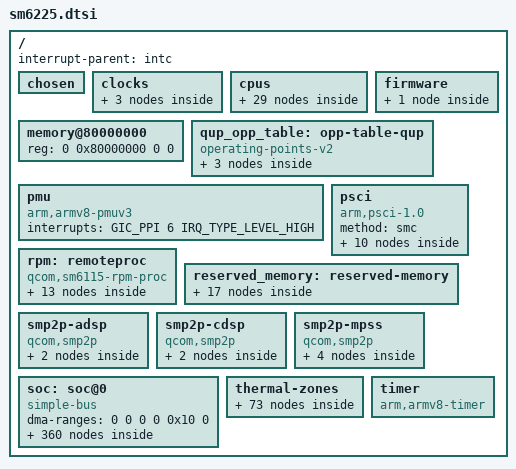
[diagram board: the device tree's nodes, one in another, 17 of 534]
// SPDX-License-Identifier: (GPL-2.0+ OR BSD-3-Clause)
/*
 * SoC device tree for SM6225
 * Copyright (c) 2025, Ivaylo Ivanov <ivo.ivanov.ivanov1@gmail.com>
 */

#include <dt-bindings/clock/qcom,gcc-sm6225.h>
#include <dt-bindings/clock/qcom,dispcc-sm6225.h>
#include <dt-bindings/clock/qcom,sm6225-gpucc.h>
#include <dt-bindings/clock/qcom,rpmcc.h>
#include <dt-bindings/dma/qcom-gpi.h>
#include <dt-bindings/firmware/qcom,scm.h>
#include <dt-bindings/gpio/gpio.h>
#include <dt-bindings/interconnect/qcom,rpm-icc.h>
#include <dt-bindings/interconnect/qcom,sm6115.h>
#include <dt-bindings/interrupt-controller/arm-gic.h>
#include <dt-bindings/power/qcom-rpmpd.h>
#include <dt-bindings/soc/qcom,gpr.h>
#include <dt-bindings/sound/qcom,q6dsp-lpass-ports.h>
#include <dt-bindings/thermal/thermal.h>

/ {
	interrupt-parent = <&intc>;

	#address-cells = <2>;
	#size-cells = <2>;

	chosen { };

	clocks {
		xo_board: xo-board {
			compatible = "fixed-clock";
			#clock-cells = <0>;
		};

		sleep_clk: sleep-clk {
			compatible = "fixed-clock";
			#clock-cells = <0>;
		};

		usb3_phy_wrapper_gcc_usb30_pipe_clk: usb3_phy_wrapper_gcc_usb30_pipe_clk {
			compatible = "fixed-clock";
			#clock-cells = <0>;
			clock-frequency = <1000>;
			clock-output-names = "usb3_phy_wrapper_gcc_usb30_pipe_clk";
		};
	};

	cpus {
		#address-cells = <2>;
		#size-cells = <0>;

		cpu0: cpu@0 {
			device_type = "cpu";
			compatible = "qcom,kryo260";
			reg = <0x0 0x0>;
			clocks = <&cpufreq_hw 0>;
			capacity-dmips-mhz = <1024>;
			dynamic-power-coefficient = <100>;
			enable-method = "psci";
			next-level-cache = <&l2_0>;
			qcom,freq-domain = <&cpufreq_hw 0>;
			power-domains = <&cpu_pd0>;
			power-domain-names = "psci";
			l2_0: l2-cache {
				compatible = "cache";
				cache-level = <2>;
				cache-unified;
			};
		};

		cpu1: cpu@1 {
			device_type = "cpu";
			compatible = "qcom,kryo260";
			reg = <0x0 0x1>;
			clocks = <&cpufreq_hw 0>;
			capacity-dmips-mhz = <1024>;
			dynamic-power-coefficient = <100>;
			enable-method = "psci";
			next-level-cache = <&l2_0>;
			qcom,freq-domain = <&cpufreq_hw 0>;
			power-domains = <&cpu_pd1>;
			power-domain-names = "psci";
		};

		cpu2: cpu@2 {
			device_type = "cpu";
			compatible = "qcom,kryo260";
			reg = <0x0 0x2>;
			clocks = <&cpufreq_hw 0>;
			capacity-dmips-mhz = <1024>;
			dynamic-power-coefficient = <100>;
			enable-method = "psci";
			next-level-cache = <&l2_0>;
			qcom,freq-domain = <&cpufreq_hw 0>;
			power-domains = <&cpu_pd2>;
			power-domain-names = "psci";
		};

		cpu3: cpu@3 {
			device_type = "cpu";
			compatible = "qcom,kryo260";
			reg = <0x0 0x3>;
			clocks = <&cpufreq_hw 0>;
			capacity-dmips-mhz = <1024>;
			dynamic-power-coefficient = <100>;
			enable-method = "psci";
			next-level-cache = <&l2_0>;
			qcom,freq-domain = <&cpufreq_hw 0>;
			power-domains = <&cpu_pd3>;
			power-domain-names = "psci";
		};

		cpu4: cpu@100 {
			device_type = "cpu";
			compatible = "qcom,kryo260";
			reg = <0x0 0x100>;
			clocks = <&cpufreq_hw 1>;
			enable-method = "psci";
			capacity-dmips-mhz = <1638>;
			dynamic-power-coefficient = <282>;
			next-level-cache = <&l2_1>;
			qcom,freq-domain = <&cpufreq_hw 1>;
			power-domains = <&cpu_pd4>;
			power-domain-names = "psci";
			l2_1: l2-cache {
				compatible = "cache";
				cache-level = <2>;
				cache-unified;
			};
		};

		cpu5: cpu@101 {
			device_type = "cpu";
			compatible = "qcom,kryo260";
			reg = <0x0 0x101>;
			clocks = <&cpufreq_hw 1>;
			capacity-dmips-mhz = <1638>;
			dynamic-power-coefficient = <282>;
			enable-method = "psci";
			next-level-cache = <&l2_1>;
			qcom,freq-domain = <&cpufreq_hw 1>;
			power-domains = <&cpu_pd5>;
			power-domain-names = "psci";
		};

		cpu6: cpu@102 {
			device_type = "cpu";
			compatible = "qcom,kryo260";
			reg = <0x0 0x102>;
			clocks = <&cpufreq_hw 1>;
			capacity-dmips-mhz = <1638>;
			dynamic-power-coefficient = <282>;
			enable-method = "psci";
			next-level-cache = <&l2_1>;
			qcom,freq-domain = <&cpufreq_hw 1>;
			power-domains = <&cpu_pd6>;
			power-domain-names = "psci";
		};

		cpu7: cpu@103 {
			device_type = "cpu";
			compatible = "qcom,kryo260";
			reg = <0x0 0x103>;
			clocks = <&cpufreq_hw 1>;
			capacity-dmips-mhz = <1638>;
			dynamic-power-coefficient = <282>;
			enable-method = "psci";
			next-level-cache = <&l2_1>;
			qcom,freq-domain = <&cpufreq_hw 1>;
			power-domains = <&cpu_pd7>;
			power-domain-names = "psci";
		};

		cpu-map {
			cluster0 {
				core0 {
					cpu = <&cpu0>;
				};

				core1 {
					cpu = <&cpu1>;
				};

				core2 {
					cpu = <&cpu2>;
				};

				core3 {
					cpu = <&cpu3>;
				};
			};

			cluster1 {
				core0 {
					cpu = <&cpu4>;
				};

				core1 {
					cpu = <&cpu5>;
				};

				core2 {
					cpu = <&cpu6>;
				};

				core3 {
					cpu = <&cpu7>;
				};
			};
		};

		idle-states {
			entry-method = "psci";

			little_cpu_sleep_0: cpu-sleep-0-0 {
				compatible = "arm,idle-state";
				idle-state-name = "silver-rail-power-collapse";
				arm,psci-suspend-param = <0x40000003>;
				entry-latency-us = <290>;
				exit-latency-us = <376>;
				min-residency-us = <1182>;
				local-timer-stop;
			};

			big_cpu_sleep_0: cpu-sleep-1-0 {
				compatible = "arm,idle-state";
				idle-state-name = "gold-rail-power-collapse";
				arm,psci-suspend-param = <0x40000003>;
				entry-latency-us = <297>;
				exit-latency-us = <324>;
				min-residency-us = <1110>;
				local-timer-stop;
			};
		};

		domain-idle-states {
			cluster_0_sleep_0: cluster-sleep-0-0 {
				/* GDHS */
				compatible = "domain-idle-state";
				arm,psci-suspend-param = <0x40000022>;
				entry-latency-us = <360>;
				exit-latency-us = <421>;
				min-residency-us = <782>;
			};

			cluster_0_sleep_1: cluster-sleep-0-1 {
				/* Power Collapse */
				compatible = "domain-idle-state";
				arm,psci-suspend-param = <0x41000044>;
				entry-latency-us = <800>;
				exit-latency-us = <2118>;
				min-residency-us = <7376>;
			};

			cluster_1_sleep_0: cluster-sleep-1-0 {
				/* GDHS */
				compatible = "domain-idle-state";
				arm,psci-suspend-param = <0x40000042>;
				entry-latency-us = <314>;
				exit-latency-us = <345>;
				min-residency-us = <660>;
			};

			cluster_1_sleep_1: cluster-sleep-1-1 {
				/* Power Collapse */
				compatible = "domain-idle-state";
				arm,psci-suspend-param = <0x41000044>;
				entry-latency-us = <640>;
				exit-latency-us = <1654>;
				min-residency-us = <8094>;
			};
		};
	};

	firmware {
		scm: scm {
			compatible = "qcom,scm-sm6115", "qcom,scm";
			#reset-cells = <1>;
			interconnects = <&system_noc MASTER_CRYPTO_CORE0 RPM_ALWAYS_TAG
					 &bimc SLAVE_EBI_CH0 RPM_ALWAYS_TAG>;
		};
	};

	memory@80000000 {
		device_type = "memory";
		/* We expect the bootloader to fill in the size */
		reg = <0 0x80000000 0 0>;
	};

	qup_opp_table: opp-table-qup {
		compatible = "operating-points-v2";

		opp-75000000 {
			opp-hz = /bits/ 64 <75000000>;
			required-opps = <&rpmpd_opp_low_svs>;
		};

		opp-100000000 {
			opp-hz = /bits/ 64 <100000000>;
			required-opps = <&rpmpd_opp_svs>;
		};

		opp-128000000 {
			opp-hz = /bits/ 64 <128000000>;
			required-opps = <&rpmpd_opp_nom>;
		};
	};

	pmu {
		compatible = "arm,armv8-pmuv3";
		interrupts = <GIC_PPI 6 IRQ_TYPE_LEVEL_HIGH>;
	};

	psci {
		compatible = "arm,psci-1.0";
		method = "smc";

		cpu_pd0: power-domain-cpu0 {
			#power-domain-cells = <0>;
			power-domains = <&cluster_0_pd>;
			domain-idle-states = <&little_cpu_sleep_0>;
		};

		cpu_pd1: power-domain-cpu1 {
			#power-domain-cells = <0>;
			power-domains = <&cluster_0_pd>;
			domain-idle-states = <&little_cpu_sleep_0>;
		};

		cpu_pd2: power-domain-cpu2 {
			#power-domain-cells = <0>;
			power-domains = <&cluster_0_pd>;
			domain-idle-states = <&little_cpu_sleep_0>;
		};

		cpu_pd3: power-domain-cpu3 {
			#power-domain-cells = <0>;
			power-domains = <&cluster_0_pd>;
			domain-idle-states = <&little_cpu_sleep_0>;
		};

		cpu_pd4: power-domain-cpu4 {
			#power-domain-cells = <0>;
			power-domains = <&cluster_1_pd>;
			domain-idle-states = <&big_cpu_sleep_0>;
		};

		cpu_pd5: power-domain-cpu5 {
			#power-domain-cells = <0>;
			power-domains = <&cluster_1_pd>;
			domain-idle-states = <&big_cpu_sleep_0>;
		};

		cpu_pd6: power-domain-cpu6 {
			#power-domain-cells = <0>;
			power-domains = <&cluster_1_pd>;
			domain-idle-states = <&big_cpu_sleep_0>;
		};

		cpu_pd7: power-domain-cpu7 {
			#power-domain-cells = <0>;
			power-domains = <&cluster_1_pd>;
			domain-idle-states = <&big_cpu_sleep_0>;
		};

		cluster_0_pd: power-domain-cpu-cluster0 {
			#power-domain-cells = <0>;
			domain-idle-states = <&cluster_0_sleep_0>, <&cluster_0_sleep_1>;
		};

		cluster_1_pd: power-domain-cpu-cluster1 {
			#power-domain-cells = <0>;
			domain-idle-states = <&cluster_1_sleep_0>, <&cluster_1_sleep_1>;
		};
	};

	rpm: remoteproc {
		compatible = "qcom,sm6115-rpm-proc", "qcom,rpm-proc";

		glink-edge {
			compatible = "qcom,glink-rpm";

			interrupts = <GIC_SPI 194 IRQ_TYPE_EDGE_RISING>;
			qcom,rpm-msg-ram = <&rpm_msg_ram>;
			mboxes = <&apcs_glb 0>;

			rpm_requests: rpm-requests {
				compatible = "qcom,rpm-sm6115", "qcom,glink-smd-rpm";
				qcom,glink-channels = "rpm_requests";

				rpmcc: clock-controller {
					compatible = "qcom,rpmcc-sm6115", "qcom,rpmcc";
					clocks = <&xo_board>;
					clock-names = "xo";
					#clock-cells = <1>;
				};

				rpmpd: power-controller {
					compatible = "qcom,sm6115-rpmpd";
					#power-domain-cells = <1>;
					operating-points-v2 = <&rpmpd_opp_table>;

					rpmpd_opp_table: opp-table {
						compatible = "operating-points-v2";

						rpmpd_opp_min_svs: opp1 {
							opp-level = <RPM_SMD_LEVEL_MIN_SVS>;
						};

						rpmpd_opp_low_svs: opp2 {
							opp-level = <RPM_SMD_LEVEL_LOW_SVS>;
						};

						rpmpd_opp_svs: opp3 {
							opp-level = <RPM_SMD_LEVEL_SVS>;
						};

						rpmpd_opp_svs_plus: opp4 {
							opp-level = <RPM_SMD_LEVEL_SVS_PLUS>;
						};

						rpmpd_opp_nom: opp5 {
							opp-level = <RPM_SMD_LEVEL_NOM>;
						};

						rpmpd_opp_nom_plus: opp6 {
							opp-level = <RPM_SMD_LEVEL_NOM_PLUS>;
						};

						rpmpd_opp_turbo: opp7 {
							opp-level = <RPM_SMD_LEVEL_TURBO>;
						};

						rpmpd_opp_turbo_plus: opp8 {
							opp-level = <RPM_SMD_LEVEL_TURBO_NO_CPR>;
						};
					};
				};
			};
		};
	};

	reserved_memory: reserved-memory {
		#address-cells = <2>;
		#size-cells = <2>;
		ranges;

		hyp_mem: memory@45700000 {
			reg = <0x0 0x45700000 0x0 0x600000>;
			no-map;
		};

		xbl_aop_mem: memory@45e00000 {
			reg = <0x0 0x45e00000 0x0 0x140000>;
			no-map;
		};

		sec_apps_mem: memory@45fff000 {
			reg = <0x0 0x45fff000 0x0 0x1000>;
			no-map;
		};

		smem_mem: memory@46000000 {
			compatible = "qcom,smem";
			reg = <0x0 0x46000000 0x0 0x200000>;
			no-map;

			hwlocks = <&tcsr_mutex 3>;
			qcom,rpm-msg-ram = <&rpm_msg_ram>;
		};

		cdsp_sec_regions: memory@46200000 {
			reg = <0x0 0x46200000 0x0 0x1e00000>;
			no-map;
		};

		pil_modem_mem: memory@4ab00000 {
			reg = <0x0 0x4ab00000 0x0 0x6900000>;
			no-map;
		};

		pil_video_mem: memory@51400000 {
			reg = <0x0 0x51400000 0x0 0x500000>;
			no-map;
		};

		wlan_msa_mem: memory@51900000 {
			reg = <0x0 0x51900000 0x0 0x100000>;
			no-map;
		};

		pil_cdsp_mem: memory@51a00000 {
			reg = <0x0 0x51a00000 0x0 0x1e00000>;
			no-map;
		};

		pil_adsp_mem: memory@53800000 {
			reg = <0x0 0x53800000 0x0 0x2e00000>;
			no-map;
		};

		pil_ipa_fw_mem: memory@56600000 {
			reg = <0x0 0x56600000 0x0 0x10000>;
			no-map;
		};

		// pil_ipa_gsi_mem: memory@55610000 {
		// 	reg = <0x0 0x55610000 0x0 0x5000>;
		// 	no-map;
		// };

		pil_gpu_mem: memory@56615000 {
			reg = <0x0 0x56615000 0x0 0x2000>;
			no-map;
		};

		cont_splash_memory: memory@5c000000 {
			reg = <0x0 0x5c000000 0x0 0x00f00000>;
			no-map;
		};

		dfps_data_memory: memory@5cf00000 {
			reg = <0x0 0x5cf00000 0x0 0x0100000>;
			no-map;
		};

		removed_mem: memory@60000000 {
			reg = <0x0 0x60000000 0x0 0x3900000>;
			no-map;
		};

		rmtfs_mem: memory@89b01000 {
			compatible = "qcom,rmtfs-mem";
			reg = <0x0 0x89b01000 0x0 0x300000>;
			no-map;

			qcom,client-id = <1>;
			qcom,vmid = <QCOM_SCM_VMID_MSS_MSA QCOM_SCM_VMID_NAV>;
		};

		/* The ADSP audio PD's remote heap, as stock's adsp_region */
		adsp_rpc_remote_heap_mem: adsp-rpc-remote-heap {
			compatible = "shared-dma-pool";
			alloc-ranges = <0x0 0x0 0x0 0xffffffff>;
			reusable;
			alignment = <0x0 0x400000>;
			size = <0x0 0x800000>;
		};
	};

	smp2p-adsp {
		compatible = "qcom,smp2p";
		qcom,smem = <443>, <429>;

		interrupts = <GIC_SPI 279 IRQ_TYPE_EDGE_RISING>;

		mboxes = <&apcs_glb 10>;

		qcom,local-pid = <0>;
		qcom,remote-pid = <2>;

		adsp_smp2p_out: master-kernel {
			qcom,entry-name = "master-kernel";
			#qcom,smem-state-cells = <1>;
		};

		adsp_smp2p_in: slave-kernel {
			qcom,entry-name = "slave-kernel";

			interrupt-controller;
			#interrupt-cells = <2>;
		};
	};

	smp2p-cdsp {
		compatible = "qcom,smp2p";
		qcom,smem = <94>, <432>;

		interrupts = <GIC_SPI 263 IRQ_TYPE_EDGE_RISING>;

		mboxes = <&apcs_glb 30>;

		qcom,local-pid = <0>;
		qcom,remote-pid = <5>;

		cdsp_smp2p_out: master-kernel {
			qcom,entry-name = "master-kernel";
			#qcom,smem-state-cells = <1>;
		};

		cdsp_smp2p_in: slave-kernel {
			qcom,entry-name = "slave-kernel";

			interrupt-controller;
			#interrupt-cells = <2>;
		};
	};

	smp2p-mpss {
		compatible = "qcom,smp2p";
		qcom,smem = <435>, <428>;

		interrupts = <GIC_SPI 70 IRQ_TYPE_EDGE_RISING>;

		mboxes = <&apcs_glb 14>;

		qcom,local-pid = <0>;
		qcom,remote-pid = <1>;

		modem_smp2p_out: master-kernel {
			qcom,entry-name = "master-kernel";
			#qcom,smem-state-cells = <1>;
		};

		modem_smp2p_in: slave-kernel {
			qcom,entry-name = "slave-kernel";

			interrupt-controller;
			#interrupt-cells = <2>;
		};

		ipa_smp2p_out: ipa-ap-to-modem {
			qcom,entry-name = "ipa";
			#qcom,smem-state-cells = <1>;
		};

		ipa_smp2p_in: ipa-modem-to-ap {
			qcom,entry-name = "ipa";
			interrupt-controller;
			#interrupt-cells = <2>;
		};
	};

	soc: soc@0 {
		compatible = "simple-bus";
		#address-cells = <2>;
		#size-cells = <2>;
		ranges = <0 0 0 0 0x10 0>;
		dma-ranges = <0 0 0 0 0x10 0>;

		tcsr_mutex: hwlock@340000 {
			compatible = "qcom,tcsr-mutex";
			reg = <0x0 0x00340000 0x0 0x20000>;
			#hwlock-cells = <1>;
		};

		tcsr_regs: syscon@3c0000 {
			compatible = "qcom,sm6115-tcsr", "syscon";
			reg = <0x0 0x003c0000 0x0 0x40000>;
		};

		tlmm: pinctrl@500000 {
			compatible = "qcom,sm6225-tlmm";
			reg = <0x0 0x00500000 0x0 0x400000>,
			      <0x0 0x00900000 0x0 0x400000>,
			      <0x0 0x00d00000 0x0 0x400000>;
			reg-names = "west", "south", "east";
			interrupts = <GIC_SPI 227 IRQ_TYPE_LEVEL_HIGH>;
			gpio-controller;
			gpio-ranges = <&tlmm 0 0 113>;
			#gpio-cells = <2>;
			interrupt-controller;
			#interrupt-cells = <2>;

			qup_i2c0_default: qup-i2c0-default-state {
				pins = "gpio0", "gpio1";
				function = "qup0";
				drive-strength = <2>;
				bias-pull-up;
			};

			qup_i2c1_default: qup-i2c1-default-state {
				pins = "gpio4", "gpio5";
				function = "qup1";
				drive-strength = <2>;
				bias-pull-up;
			};

			qup_i2c2_default: qup-i2c2-default-state {
				pins = "gpio6", "gpio7";
				function = "qup2";
				drive-strength = <2>;
				bias-pull-up;
			};

			qup_i2c3_default: qup-i2c3-default-state {
				pins = "gpio8", "gpio9";
				function = "qup3";
				drive-strength = <2>;
				bias-pull-up;
			};

			qup_i2c4_default: qup-i2c4-default-state {
				pins = "gpio12", "gpio13";
				function = "qup4";
				drive-strength = <2>;
				bias-pull-up;
			};

			qup_i2c5_default: qup-i2c5-default-state {
				pins = "gpio14", "gpio15";
				function = "qup5";
				drive-strength = <2>;
				bias-pull-up;
			};

			qup_spi0_default: qup-spi0-default-state {
				pins = "gpio0", "gpio1","gpio2", "gpio3";
				function = "qup0";
				drive-strength = <2>;
				bias-pull-up;
			};

			qup_spi1_default: qup-spi1-default-state {
				pins = "gpio4", "gpio5", "gpio69", "gpio70";
				function = "qup1";
				drive-strength = <2>;
				bias-pull-up;
			};

			qup_spi2_default: qup-spi2-default-state {
				pins = "gpio6", "gpio7", "gpio71", "gpio80";
				function = "qup2";
				drive-strength = <2>;
				bias-pull-up;
			};

			qup_spi3_default: qup-spi3-default-state {
				pins = "gpio8", "gpio9", "gpio10", "gpio11";
				function = "qup3";
				drive-strength = <2>;
				bias-pull-up;
			};

			qup_spi4_default: qup-spi4-default-state {
				pins = "gpio12", "gpio13", "gpio96", "gpio97";
				function = "qup4";
				drive-strength = <2>;
				bias-pull-up;
			};

			qup_spi5_default: qup-spi5-default-state {
				pins = "gpio14", "gpio15", "gpio16", "gpio17";
				function = "qup5";
				drive-strength = <2>;
				bias-pull-up;
			};

			qup_uart3_default: qup-uart3-default-state {
				qup_uart3_tx: tx-pin {
					pins = "gpio10";
					function = "qup3";
				};

				qup_uart3_rx: rx-pin {
					pins = "gpio11";
					function = "qup3";
				};
			};

			qup_uart3_4pin: qup-uart3-4pin-state {
				qup_uart3_4pin_cts: cts-pins {
					pins = "gpio8";
					function = "qup3";
				};

				qup_uart3_4pin_rts_tx: rts-tx-pins {
					pins = "gpio9", "gpio10";
					function = "qup3";
				};

				qup_uart3_4pin_rx: rx-pins {
					pins = "gpio11";
					function = "qup3";
				};
			};

			cci0_default: cci0-default-state {
				pins = "gpio22", "gpio23";
				function = "cci_i2c";
				drive-strength = <2>;
				bias-pull-up;
			};

			cci0_sleep: cci0-sleep-state {
				pins = "gpio22", "gpio23";
				function = "cci_i2c";
				drive-strength = <2>;
				bias-pull-down;
			};

			cci1_default: cci1-default-state {
				pins = "gpio29", "gpio30";
				function = "cci_i2c";
				drive-strength = <2>;
				bias-pull-up;
			};

			cci1_sleep: cci1-sleep-state {
				pins = "gpio29", "gpio30";
				function = "cci_i2c";
				drive-strength = <2>;
				bias-pull-down;
			};

			sdc1_state_on: sdc1-on-state {
				clk-pins {
					pins = "sdc1_clk";
					bias-disable;
					drive-strength = <16>;
				};

				cmd-pins {
					pins = "sdc1_cmd";
					bias-pull-up;
					drive-strength = <10>;
				};

				data-pins {
					pins = "sdc1_data";
					bias-pull-up;
					drive-strength = <10>;
				};

				rclk-pins {
					pins = "sdc1_rclk";
					bias-pull-down;
				};
			};

			sdc1_state_off: sdc1-off-state {
				clk-pins {
					pins = "sdc1_clk";
					bias-disable;
					drive-strength = <2>;
				};

				cmd-pins {
					pins = "sdc1_cmd";
					bias-pull-up;
					drive-strength = <2>;
				};

				data-pins {
					pins = "sdc1_data";
					bias-pull-up;
					drive-strength = <2>;
				};

				rclk-pins {
					pins = "sdc1_rclk";
					bias-pull-down;
				};
			};

			sdc2_state_on: sdc2-on-state {
				clk-pins {
					pins = "sdc2_clk";
					bias-disable;
					drive-strength = <16>;
				};

				cmd-pins {
					pins = "sdc2_cmd";
					bias-pull-up;
					drive-strength = <10>;
				};

				data-pins {
					pins = "sdc2_data";
					bias-pull-up;
					drive-strength = <10>;
				};
			};

			sdc2_state_off: sdc2-off-state {
				clk-pins {
					pins = "sdc2_clk";
					bias-disable;
					drive-strength = <2>;
				};

				cmd-pins {
					pins = "sdc2_cmd";
					bias-pull-up;
					drive-strength = <2>;
				};

				data-pins {
					pins = "sdc2_data";
					bias-pull-up;
					drive-strength = <2>;
				};
			};
		};

		lpass_tlmm: pinctrl@a7c0000 {
			compatible = "qcom,sm6115-lpass-lpi-pinctrl";
			reg = <0x0 0x0a7c0000 0x0 0x20000>,
			      <0x0 0x0a950000 0x0 0x10000>;

			clocks = <&q6prmcc LPASS_HW_DCODEC_VOTE LPASS_CLK_ATTRIBUTE_COUPLE_NO>;
			clock-names = "audio";

			gpio-controller;
			#gpio-cells = <2>;
			gpio-ranges = <&lpass_tlmm 0 0 19>;

			/*
			 * Primary MI2S. The driver calls it "i2s1"; these four
			 * pins carry it in their second mux function, the first
			 * being dmic01/dmic23 -- which is why a board using the
			 * primary port has to leave the LPI DMICs alone.
			 *
			 * Both data lines are muxed. The port is shared by two
			 * amplifiers on this generation of hardware and vendor
			 * device trees describe sd0 and sd1 together; muxing an
			 * unused one costs nothing, while omitting a used one
			 * is silent.
			 */
			lpi_i2s1_active: lpi-i2s1-active-state {
				sck-pins {
					pins = "gpio6";
					function = "i2s1_clk";
					bias-disable;
					drive-strength = <8>;
				};

				ws-pins {
					pins = "gpio7";
					function = "i2s1_ws";
					bias-disable;
					drive-strength = <8>;
				};

				data-pins {
					pins = "gpio8", "gpio9";
					function = "i2s1_data";
					bias-disable;
					drive-strength = <8>;
				};
			};

			lpass_tx_swr_active: lpass-tx-swr-active-state {
				clk-pins {
					pins = "gpio0";
					function = "swr_tx_clk";
					drive-strength = <10>;
					slew-rate = <3>;
					bias-disable;
				};

				data-pins {
					pins = "gpio1", "gpio2";
					function = "swr_tx_data";
					drive-strength = <10>;
					slew-rate = <3>;
					bias-bus-hold;
				};
			};

			lpass_rx_swr_active: lpass-rx-swr-active-state {
				clk-pins {
					pins = "gpio3";
					function = "swr_rx_clk";
					drive-strength = <10>;
					slew-rate = <3>;
					bias-disable;
				};

				data-pins {
					pins = "gpio4", "gpio5";
					function = "swr_rx_data";
					drive-strength = <10>;
					slew-rate = <3>;
					bias-bus-hold;
				};
			};
		};

		gcc: clock-controller@1400000 {
			compatible = "qcom,gcc-sm6225";
			reg = <0x0 0x01400000 0x0 0x1f0000>;
			clocks = <&rpmcc RPM_SMD_XO_CLK_SRC>,
				 <&rpmcc RPM_SMD_XO_A_CLK_SRC>,
				 <&sleep_clk>;
			clock-names = "bi_tcxo", "bi_tcxo_ao", "sleep_clk";
			#clock-cells = <1>;
			#reset-cells = <1>;
			#power-domain-cells = <1>;
		};

		usb_hsphy: phy@1613000 {
			compatible = "qcom,sm6375-usb-hs-phy", "qcom,usb-snps-hs-7nm-phy";
			reg = <0x0 0x01613000 0x0 0x180>;
			#phy-cells = <0>;

			clocks = <&gcc GCC_AHB2PHY_USB_CLK>, <&rpmcc RPM_SMD_XO_CLK_SRC>;
			clock-names = "cfg_ahb", "ref";

			resets = <&gcc GCC_QUSB2PHY_PRIM_BCR>;

			status = "disabled";
		};

		cryptobam: dma-controller@1b04000 {
			compatible = "qcom,bam-v1.7.4", "qcom,bam-v1.7.0";
			reg = <0x0 0x01b04000 0x0 0x24000>;
			interrupts = <GIC_SPI 247 IRQ_TYPE_LEVEL_HIGH>;
			clocks = <&rpmcc RPM_SMD_CE1_CLK>;
			clock-names = "bam_clk";
			#dma-cells = <1>;
			qcom,ee = <0>;
			qcom,controlled-remotely;
			iommus = <&apps_smmu 0x92 0>,
				 <&apps_smmu 0x94 0x11>,
				 <&apps_smmu 0x96 0x11>,
				 <&apps_smmu 0x98 0x1>,
				 <&apps_smmu 0x9F 0>;
		};

		crypto: crypto@1b20000 {
			compatible = "qcom,sm6115-qce", "qcom,ipq4019-qce", "qcom,qce";
			reg = <0x0 0x01b20000 0x0 0x20000>;
			clocks = <&rpmcc RPM_SMD_CE1_CLK>;
			clock-names = "core";

			dmas = <&cryptobam 6>, <&cryptobam 7>;
			dma-names = "rx", "tx";
			iommus = <&apps_smmu 0x92 0>,
				 <&apps_smmu 0x94 0x11>,
				 <&apps_smmu 0x96 0x11>,
				 <&apps_smmu 0x98 0x1>,
				 <&apps_smmu 0x9F 0>;
		};

		usb_qmpphy: phy@1615000 {
			compatible = "qcom,sm6115-qmp-usb3-phy";
			reg = <0x0 0x01615000 0x0 0x1000>;

			clocks = <&gcc GCC_AHB2PHY_USB_CLK>,
				 <&gcc GCC_USB3_PRIM_CLKREF_CLK>,
				 <&gcc GCC_USB3_PRIM_PHY_COM_AUX_CLK>,
				 <&gcc GCC_USB3_PRIM_PHY_PIPE_CLK>;
			clock-names = "cfg_ahb",
				      "ref",
				      "com_aux",
				      "pipe";

			resets = <&gcc GCC_USB3_PHY_PRIM_SP0_BCR>,
				 <&gcc GCC_USB3PHY_PHY_PRIM_SP0_BCR>;
			reset-names = "phy", "phy_phy";

			#clock-cells = <0>;
			clock-output-names = "usb3_phy_pipe_clk_src";

			#phy-cells = <0>;
			orientation-switch;

			qcom,tcsr-reg = <&tcsr_regs 0xb244>;

			status = "disabled";

			ports {
				#address-cells = <1>;
				#size-cells = <0>;

				port@0 {
					reg = <0>;

					usb_qmpphy_out: endpoint {
					};
				};

				port@1 {
					reg = <1>;

					usb_qmpphy_usb_ss_in: endpoint {
						remote-endpoint = <&usb_dwc3_ss>;
					};
				};
			};
		};

		system_noc: interconnect@1880000 {
			compatible = "qcom,sm6115-snoc";
			reg = <0x0 0x01880000 0x0 0x5f080>;
			clocks = <&gcc GCC_SYS_NOC_CPUSS_AHB_CLK>,
				 <&gcc GCC_SYS_NOC_UFS_PHY_AXI_CLK>,
				 <&gcc GCC_SYS_NOC_USB3_PRIM_AXI_CLK>,
				 <&rpmcc RPM_SMD_IPA_CLK>;
			clock-names = "cpu_axi",
				      "ufs_axi",
				      "usb_axi",
				      "ipa";
			#interconnect-cells = <2>;

			clk_virt: interconnect-clk {
				compatible = "qcom,sm6115-clk-virt";
				#interconnect-cells = <2>;
			};

			mmrt_virt: interconnect-mmrt {
				compatible = "qcom,sm6115-mmrt-virt";
				#interconnect-cells = <2>;
			};

			mmnrt_virt: interconnect-mmnrt {
				compatible = "qcom,sm6115-mmnrt-virt";
				#interconnect-cells = <2>;
			};
		};

		config_noc: interconnect@1900000 {
			compatible = "qcom,sm6115-cnoc";
			reg = <0x0 0x01900000 0x0 0x6200>;
			clocks = <&gcc GCC_CFG_NOC_USB3_PRIM_AXI_CLK>;
			clock-names = "usb_axi";
			#interconnect-cells = <2>;
		};

		qfprom@1b40000 {
			compatible = "qcom,sm6115-qfprom", "qcom,qfprom";
			reg = <0x0 0x01b40000 0x0 0x7000>;
			#address-cells = <1>;
			#size-cells = <1>;

			adsp_variant@6011 {
				reg = <0x6011 0x01>;
				bits = <0x03 0x01>;
			};

			gpu_speed_bin: gpu-speed-bin@6006 {
				reg = <0x6006 0x2>;
				bits = <5 8>;
			};

			feat_conf10@602c {
				reg = <0x602c 0x04>;
			};

			feat_conf11@6030 {
				reg = <0x6030 0x01>;
				bits = <0x00 0x08>;
			};

			gpu_gaming_bin@602d {
				reg = <0x602d 0x01>;
				bits = <0x05 0x01>;
			};

			stm@20f0 {
				reg = <0x20f0 0x04>;
			};

			feat_conf5@6018 {
				reg = <0x6018 0x04>;
			};
		};

		rng: rng@1b53000 {
			compatible = "qcom,prng-ee";
			reg = <0x0 0x01b53000 0x0 0x1000>;
			clocks = <&gcc GCC_PRNG_AHB_CLK>;
			clock-names = "core";
		};

		pmu@1b8e300 {
			compatible = "qcom,sm6115-cpu-bwmon", "qcom,sdm845-bwmon";
			reg = <0x0 0x01b8e300 0x0 0x600>;
			interrupts = <GIC_SPI 421 IRQ_TYPE_LEVEL_HIGH>;

			operating-points-v2 = <&cpu_bwmon_opp_table>;
			interconnects = <&bimc MASTER_AMPSS_M0 RPM_ACTIVE_TAG
					 &bimc SLAVE_EBI_CH0 RPM_ACTIVE_TAG>;

			cpu_bwmon_opp_table: opp-table {
				compatible = "operating-points-v2";

				opp-0 {
					opp-peak-kBps = <(200 * 4 * 1000)>;
				};

				opp-1 {
					opp-peak-kBps = <(300 * 4 * 1000)>;
				};

				opp-2 {
					opp-peak-kBps = <(451 * 4 * 1000)>;
				};

				opp-3 {
					opp-peak-kBps = <(547 * 4 * 1000)>;
				};

				opp-4 {
					opp-peak-kBps = <(681 * 4 * 1000)>;
				};

				opp-5 {
					opp-peak-kBps = <(768 * 4 * 1000)>;
				};

				opp-6 {
					opp-peak-kBps = <(1017 * 4 * 1000)>;
				};

				opp-7 {
					opp-peak-kBps = <(1353 * 4 * 1000)>;
				};

				opp-8 {
					opp-peak-kBps = <(1555 * 4 * 1000)>;
				};

				opp-9 {
					opp-peak-kBps = <(1804 * 4 * 1000)>;
				};
			};
		};

		spmi_bus: spmi@1c40000 {
			compatible = "qcom,spmi-pmic-arb";
			reg = <0x0 0x01c40000 0x0 0x1100>,
			      <0x0 0x01e00000 0x0 0x2000000>,
			      <0x0 0x03e00000 0x0 0x100000>,
			      <0x0 0x03f00000 0x0 0xa0000>,
			      <0x0 0x01c0a000 0x0 0x26000>;
			reg-names = "core", "chnls", "obsrvr", "intr", "cnfg";
			interrupt-names = "periph_irq";
			interrupts = <GIC_SPI 183 IRQ_TYPE_LEVEL_HIGH>;
			qcom,ee = <0>;
			qcom,channel = <0>;
			#address-cells = <2>;
			#size-cells = <0>;
			interrupt-controller;
			#interrupt-cells = <4>;
		};

		tsens0: thermal-sensor@4411000 {
			compatible = "qcom,sm6115-tsens", "qcom,tsens-v2";
			reg = <0x0 0x04411000 0x0 0x1ff>, /* TM */
			      <0x0 0x04410000 0x0 0x8>; /* SROT */
			#qcom,sensors = <16>;
			interrupts = <GIC_SPI 275 IRQ_TYPE_LEVEL_HIGH>,
				     <GIC_SPI 190 IRQ_TYPE_LEVEL_HIGH>;
			interrupt-names = "uplow", "critical";
			#thermal-sensor-cells = <1>;
		};

		bimc: interconnect@4480000 {
			compatible = "qcom,sm6115-bimc";
			reg = <0x0 0x04480000 0x0 0x80000>;
			#interconnect-cells = <2>;
		};

		rpm_msg_ram: sram@45f0000 {
			compatible = "qcom,rpm-msg-ram";
			reg = <0x0 0x045f0000 0x0 0x7000>;
		};

		sram@4690000 {
			compatible = "qcom,rpm-stats";
			reg = <0x0 0x04690000 0x0 0x10000>;
		};

		sdhc_1: mmc@4744000 {
			compatible = "qcom,sm6115-sdhci", "qcom,sdhci-msm-v5";
			reg = <0x0 0x04744000 0x0 0x1000>,
			      <0x0 0x04745000 0x0 0x1000>,
			      <0x0 0x04748000 0x0 0x8000>;
			reg-names = "hc", "cqhci", "ice";

			interrupts = <GIC_SPI 348 IRQ_TYPE_LEVEL_HIGH>,
				     <GIC_SPI 352 IRQ_TYPE_LEVEL_HIGH>;
			interrupt-names = "hc_irq", "pwr_irq";

			clocks = <&gcc GCC_SDCC1_AHB_CLK>,
				 <&gcc GCC_SDCC1_APPS_CLK>,
				 <&rpmcc RPM_SMD_XO_CLK_SRC>,
				 <&gcc GCC_SDCC1_ICE_CORE_CLK>;
			clock-names = "iface", "core", "xo", "ice";

			resets = <&gcc GCC_SDCC1_BCR>;

			power-domains = <&rpmpd SM6115_VDDCX>;
			operating-points-v2 = <&sdhc1_opp_table>;
			iommus = <&apps_smmu 0x00c0 0x0>;
			interconnects = <&system_noc MASTER_SDCC_1 RPM_ALWAYS_TAG
					 &bimc SLAVE_EBI_CH0 RPM_ALWAYS_TAG>,
					<&bimc MASTER_AMPSS_M0 RPM_ALWAYS_TAG
					 &config_noc SLAVE_SDCC_1 RPM_ALWAYS_TAG>;
			interconnect-names = "sdhc-ddr",
					     "cpu-sdhc";

			bus-width = <8>;
			status = "disabled";

			sdhc1_opp_table: opp-table {
				compatible = "operating-points-v2";

				opp-100000000 {
					opp-hz = /bits/ 64 <100000000>;
					required-opps = <&rpmpd_opp_low_svs>;
					opp-peak-kBps = <250000 133320>;
					opp-avg-kBps = <102400 65000>;
				};

				opp-192000000 {
					opp-hz = /bits/ 64 <192000000>;
					required-opps = <&rpmpd_opp_low_svs>;
					opp-peak-kBps = <800000 300000>;
					opp-avg-kBps = <204800 200000>;
				};

				opp-384000000 {
					opp-hz = /bits/ 64 <384000000>;
					required-opps = <&rpmpd_opp_svs_plus>;
					opp-peak-kBps = <800000 300000>;
					opp-avg-kBps = <204800 200000>;
				};
			};
		};

		sdhc_2: mmc@4784000 {
			compatible = "qcom,sm6225-sdhci", "qcom,sdhci-msm-v5";
			reg = <0x0 0x04784000 0x0 0x1000>;
			reg-names = "hc";

			interrupts = <GIC_SPI 350 IRQ_TYPE_LEVEL_HIGH>,
				     <GIC_SPI 353 IRQ_TYPE_LEVEL_HIGH>;
			interrupt-names = "hc_irq", "pwr_irq";

			clocks = <&gcc GCC_SDCC2_AHB_CLK>,
				 <&gcc GCC_SDCC2_APPS_CLK>,
				 <&rpmcc RPM_SMD_XO_CLK_SRC>;
			clock-names = "iface", "core", "xo";

			power-domains = <&rpmpd SM6115_VDDCX>;
			operating-points-v2 = <&sdhc2_opp_table>;
			iommus = <&apps_smmu 0xa0 0x0>;
			resets = <&gcc GCC_SDCC2_BCR>;
			interconnects = <&system_noc MASTER_SDCC_2 RPM_ALWAYS_TAG
					 &bimc SLAVE_EBI_CH0 RPM_ALWAYS_TAG>,
					<&bimc MASTER_AMPSS_M0 RPM_ALWAYS_TAG
					 &config_noc SLAVE_SDCC_2 RPM_ALWAYS_TAG>;
			interconnect-names = "sdhc-ddr",
					     "cpu-sdhc";

			// bus-width = <4>;
			qcom,dll-config = <0x0007642c>;
			qcom,ddr-config = <0x80040873>;
			status = "disabled";

			sdhc2_opp_table: opp-table {
				compatible = "operating-points-v2";

				opp-100000000 {
					opp-hz = /bits/ 64 <100000000>;
					required-opps = <&rpmpd_opp_low_svs>;
					opp-peak-kBps = <250000 133320>;
					opp-avg-kBps = <261438 150000>;
				};

				opp-202000000 {
					opp-hz = /bits/ 64 <202000000>;
					required-opps = <&rpmpd_opp_nom>;
					opp-peak-kBps = <800000 300000>;
					opp-avg-kBps = <261438 300000>;
				};
			};
		};

		ufs_mem_hc: ufshc@4804000 {
			compatible = "qcom,sm6115-ufshc", "qcom,ufshc",
				     "jedec,ufs-2.0";
			reg = <0x0 0x04804000 0x0 0x3000>,
			      <0x0 0x04810000 0x0 0x8000>;
			reg-names = "std", "ice";
			interrupts = <GIC_SPI 356 IRQ_TYPE_LEVEL_HIGH>;
			phys = <&ufs_mem_phy>;
			phy-names = "ufsphy";
			lanes-per-direction = <2>;
			#reset-cells = <1>;
			resets = <&gcc GCC_UFS_PHY_BCR>;
			reset-names = "rst";

			power-domains = <&gcc GCC_UFS_PHY_GDSC>;

			iommus = <&apps_smmu 0x100 0>;

			clocks = <&gcc GCC_UFS_PHY_AXI_CLK>,
				 <&gcc GCC_SYS_NOC_UFS_PHY_AXI_CLK>,
				 <&gcc GCC_UFS_PHY_AHB_CLK>,
				 <&gcc GCC_UFS_PHY_UNIPRO_CORE_CLK>,
				 <&rpmcc RPM_SMD_XO_CLK_SRC>,
				 <&gcc GCC_UFS_PHY_TX_SYMBOL_0_CLK>,
				 <&gcc GCC_UFS_PHY_RX_SYMBOL_0_CLK>,
				 <&gcc GCC_UFS_PHY_RX_SYMBOL_1_CLK>,
				 <&gcc GCC_UFS_PHY_ICE_CORE_CLK>;
			clock-names = "core_clk",
				      "bus_aggr_clk",
				      "iface_clk",
				      "core_clk_unipro",
				      "ref_clk",
				      "tx_lane0_sync_clk",
				      "rx_lane0_sync_clk",
				      "rx_lane1_sync_clk",
				      "ice_core_clk";
			freq-table-hz = <50000000 200000000>,
					<0 0>,
					<0 0>,
					<37500000 150000000>,
					<0 0>,
					<0 0>,
					<0 0>,
					<0 0>,
					<75000000 300000000>;

			status = "disabled";
		};

		ufs_mem_phy: phy@4807000 {
			compatible = "qcom,sm6225-qmp-ufs-phy";
			reg = <0x0 0x04807000 0x0 0x1000>;

			clocks = <&rpmcc RPM_SMD_XO_CLK_SRC>,
				 <&gcc GCC_UFS_PHY_PHY_AUX_CLK>,
				 <&gcc GCC_UFS_CLKREF_CLK>;
			clock-names = "ref",
				      "ref_aux",
				      "qref";

			power-domains = <&gcc GCC_UFS_PHY_GDSC>;

			resets = <&ufs_mem_hc 0>;
			reset-names = "ufsphy";

			#phy-cells = <0>;

			status = "disabled";
		};

		gpi_dma0: dma-controller@4a00000 {
			compatible = "qcom,sm6115-gpi-dma", "qcom,sm6350-gpi-dma";
			reg = <0x0 0x04a00000 0x0 0x60000>;
			interrupts = <GIC_SPI 335 IRQ_TYPE_LEVEL_HIGH>,
				     <GIC_SPI 336 IRQ_TYPE_LEVEL_HIGH>,
				     <GIC_SPI 337 IRQ_TYPE_LEVEL_HIGH>,
				     <GIC_SPI 338 IRQ_TYPE_LEVEL_HIGH>,
				     <GIC_SPI 339 IRQ_TYPE_LEVEL_HIGH>,
				     <GIC_SPI 340 IRQ_TYPE_LEVEL_HIGH>,
				     <GIC_SPI 341 IRQ_TYPE_LEVEL_HIGH>,
				     <GIC_SPI 342 IRQ_TYPE_LEVEL_HIGH>,
				     <GIC_SPI 343 IRQ_TYPE_LEVEL_HIGH>,
				     <GIC_SPI 344 IRQ_TYPE_LEVEL_HIGH>;
			dma-channels = <10>;
			dma-channel-mask = <0xf>;
			iommus = <&apps_smmu 0xf6 0x0>;
			#dma-cells = <3>;
			status = "disabled";
		};

		qupv3_id_0: geniqup@4ac0000 {
			compatible = "qcom,geni-se-qup";
			reg = <0x0 0x04ac0000 0x0 0x2000>;
			clock-names = "m-ahb", "s-ahb";
			clocks = <&gcc GCC_QUPV3_WRAP_0_M_AHB_CLK>,
				 <&gcc GCC_QUPV3_WRAP_0_S_AHB_CLK>;
			#address-cells = <2>;
			#size-cells = <2>;
			iommus = <&apps_smmu 0xe3 0x0>;
			ranges;
			status = "disabled";

			i2c0: i2c@4a80000 {
				compatible = "qcom,geni-i2c";
				reg = <0x0 0x04a80000 0x0 0x4000>;
				clock-names = "se";
				clocks = <&gcc GCC_QUPV3_WRAP0_S0_CLK>;
				pinctrl-names = "default";
				pinctrl-0 = <&qup_i2c0_default>;
				interrupts = <GIC_SPI 327 IRQ_TYPE_LEVEL_HIGH>;
				dmas = <&gpi_dma0 0 0 QCOM_GPI_I2C>,
				       <&gpi_dma0 1 0 QCOM_GPI_I2C>;
				dma-names = "tx", "rx";
				#address-cells = <1>;
				#size-cells = <0>;
				status = "disabled";
			};

			spi0: spi@4a80000 {
				compatible = "qcom,geni-spi";
				reg = <0x0 0x04a80000 0x0 0x4000>;
				clock-names = "se";
				clocks = <&gcc GCC_QUPV3_WRAP0_S0_CLK>;
				pinctrl-names = "default";
				pinctrl-0 = <&qup_spi0_default>;
				interrupts = <GIC_SPI 327 IRQ_TYPE_LEVEL_HIGH>;
				dmas = <&gpi_dma0 0 0 QCOM_GPI_SPI>,
				       <&gpi_dma0 1 0 QCOM_GPI_SPI>;
				dma-names = "tx", "rx";
				spi-max-frequency = <50000000>;
				#address-cells = <1>;
				#size-cells = <0>;
				status = "disabled";
			};

			i2c1: i2c@4a84000 {
				compatible = "qcom,geni-i2c";
				reg = <0x0 0x04a84000 0x0 0x4000>;
				clock-names = "se";
				clocks = <&gcc GCC_QUPV3_WRAP0_S1_CLK>;
				pinctrl-names = "default";
				pinctrl-0 = <&qup_i2c1_default>;
				interrupts = <GIC_SPI 328 IRQ_TYPE_LEVEL_HIGH>;
				dmas = <&gpi_dma0 0 1 QCOM_GPI_I2C>,
				       <&gpi_dma0 1 1 QCOM_GPI_I2C>;
				dma-names = "tx", "rx";
				#address-cells = <1>;
				#size-cells = <0>;
				status = "disabled";
			};

			spi1: spi@4a84000 {
				compatible = "qcom,geni-spi";
				reg = <0x0 0x04a84000 0x0 0x4000>;
				clock-names = "se";
				clocks = <&gcc GCC_QUPV3_WRAP0_S1_CLK>;
				pinctrl-names = "default";
				pinctrl-0 = <&qup_spi1_default>;
				interrupts = <GIC_SPI 328 IRQ_TYPE_LEVEL_HIGH>;
				dmas = <&gpi_dma0 0 1 QCOM_GPI_SPI>,
				       <&gpi_dma0 1 1 QCOM_GPI_SPI>;
				dma-names = "tx", "rx";
				interconnects = <&clk_virt MASTER_QUP_CORE_0 RPM_ALWAYS_TAG
						 &clk_virt SLAVE_QUP_CORE_0 RPM_ALWAYS_TAG>,
						<&bimc MASTER_AMPSS_M0 RPM_ALWAYS_TAG
						 &config_noc SLAVE_QUP_0 RPM_ALWAYS_TAG>,
						<&system_noc MASTER_QUP_0 RPM_ALWAYS_TAG
						 &bimc SLAVE_EBI_CH0 RPM_ALWAYS_TAG>;
				interconnect-names = "qup-core",
						     "qup-config",
						     "qup-memory";
				#address-cells = <1>;
				#size-cells = <0>;
				status = "disabled";
			};

			i2c2: i2c@4a88000 {
				compatible = "qcom,geni-i2c";
				reg = <0x0 0x04a88000 0x0 0x4000>;
				clock-names = "se";
				clocks = <&gcc GCC_QUPV3_WRAP0_S2_CLK>;
				pinctrl-names = "default";
				pinctrl-0 = <&qup_i2c2_default>;
				interrupts = <GIC_SPI 329 IRQ_TYPE_LEVEL_HIGH>;
				dmas = <&gpi_dma0 0 2 QCOM_GPI_I2C>,
				       <&gpi_dma0 1 2 QCOM_GPI_I2C>;
				dma-names = "tx", "rx";
				// interconnects = <&clk_virt MASTER_QUP_CORE_0 RPM_ALWAYS_TAG
				// 		 &clk_virt SLAVE_QUP_CORE_0 RPM_ALWAYS_TAG>,
				// 		<&bimc MASTER_AMPSS_M0 RPM_ALWAYS_TAG
				// 		 &config_noc SLAVE_QUP_0 RPM_ALWAYS_TAG>,
				// 		<&system_noc MASTER_QUP_0 RPM_ALWAYS_TAG
				// 		 &bimc SLAVE_EBI_CH0 RPM_ALWAYS_TAG>;
				// interconnect-names = "qup-core",
				// 		     "qup-config",
				// 		     "qup-memory";
				#address-cells = <1>;
				#size-cells = <0>;
				status = "disabled";
			};

			spi2: spi@4a88000 {
				compatible = "qcom,geni-spi";
				reg = <0x0 0x04a88000 0x0 0x4000>;
				clock-names = "se";
				clocks = <&gcc GCC_QUPV3_WRAP0_S2_CLK>;
				pinctrl-names = "default";
				pinctrl-0 = <&qup_spi2_default>;
				interrupts = <GIC_SPI 329 IRQ_TYPE_LEVEL_HIGH>;
				dmas = <&gpi_dma0 0 2 QCOM_GPI_SPI>,
				       <&gpi_dma0 1 2 QCOM_GPI_SPI>;
				dma-names = "tx", "rx";
				interconnects = <&clk_virt MASTER_QUP_CORE_0 RPM_ALWAYS_TAG
						 &clk_virt SLAVE_QUP_CORE_0 RPM_ALWAYS_TAG>,
						<&bimc MASTER_AMPSS_M0 RPM_ALWAYS_TAG
						 &config_noc SLAVE_QUP_0 RPM_ALWAYS_TAG>,
						<&system_noc MASTER_QUP_0 RPM_ALWAYS_TAG
						 &bimc SLAVE_EBI_CH0 RPM_ALWAYS_TAG>;
				interconnect-names = "qup-core",
						     "qup-config",
						     "qup-memory";
				#address-cells = <1>;
				#size-cells = <0>;
				status = "disabled";
			};

			i2c3: i2c@4a8c000 {
				compatible = "qcom,geni-i2c";
				reg = <0x0 0x04a8c000 0x0 0x4000>;
				clock-names = "se";
				clocks = <&gcc GCC_QUPV3_WRAP0_S3_CLK>;
				pinctrl-names = "default";
				pinctrl-0 = <&qup_i2c3_default>;
				interrupts = <GIC_SPI 330 IRQ_TYPE_LEVEL_HIGH>;
				dmas = <&gpi_dma0 0 3 QCOM_GPI_I2C>,
				       <&gpi_dma0 1 3 QCOM_GPI_I2C>;
				dma-names = "tx", "rx";
				interconnects = <&clk_virt MASTER_QUP_CORE_0 RPM_ALWAYS_TAG
						 &clk_virt SLAVE_QUP_CORE_0 RPM_ALWAYS_TAG>,
						<&bimc MASTER_AMPSS_M0 RPM_ALWAYS_TAG
						 &config_noc SLAVE_QUP_0 RPM_ALWAYS_TAG>,
						<&system_noc MASTER_QUP_0 RPM_ALWAYS_TAG
						 &bimc SLAVE_EBI_CH0 RPM_ALWAYS_TAG>;
				interconnect-names = "qup-core",
						     "qup-config",
						     "qup-memory";
				#address-cells = <1>;
				#size-cells = <0>;
				status = "disabled";
			};

			spi3: spi@4a8c000 {
				compatible = "qcom,geni-spi";
				reg = <0x0 0x04a8c000 0x0 0x4000>;
				clock-names = "se";
				clocks = <&gcc GCC_QUPV3_WRAP0_S3_CLK>;
				pinctrl-names = "default";
				pinctrl-0 = <&qup_spi3_default>;
				interrupts = <GIC_SPI 330 IRQ_TYPE_LEVEL_HIGH>;
				dmas = <&gpi_dma0 0 3 QCOM_GPI_SPI>,
				       <&gpi_dma0 1 3 QCOM_GPI_SPI>;
				dma-names = "tx", "rx";
				interconnects = <&clk_virt MASTER_QUP_CORE_0 RPM_ALWAYS_TAG
						 &clk_virt SLAVE_QUP_CORE_0 RPM_ALWAYS_TAG>,
						<&bimc MASTER_AMPSS_M0 RPM_ALWAYS_TAG
						 &config_noc SLAVE_QUP_0 RPM_ALWAYS_TAG>,
						<&system_noc MASTER_QUP_0 RPM_ALWAYS_TAG
						 &bimc SLAVE_EBI_CH0 RPM_ALWAYS_TAG>;
				interconnect-names = "qup-core",
						     "qup-config",
						     "qup-memory";
				#address-cells = <1>;
				#size-cells = <0>;
				status = "disabled";
			};

			uart3: serial@4a8c000 {
				compatible = "qcom,geni-uart";
				reg = <0x0 0x04a8c000 0x0 0x4000>;
				interrupts-extended = <&intc GIC_SPI 330 IRQ_TYPE_LEVEL_HIGH>;
				clocks = <&gcc GCC_QUPV3_WRAP0_S3_CLK>;
				clock-names = "se";
				pinctrl-names = "default";
				pinctrl-0 = <&qup_uart3_default>;
				power-domains = <&rpmpd SM6115_VDDCX>;
				operating-points-v2 = <&qup_opp_table>;
				interconnects = <&clk_virt MASTER_QUP_CORE_0 RPM_ALWAYS_TAG
						 &clk_virt SLAVE_QUP_CORE_0 RPM_ALWAYS_TAG>,
						<&bimc MASTER_AMPSS_M0 RPM_ALWAYS_TAG
						 &config_noc SLAVE_QUP_0 RPM_ALWAYS_TAG>;
				interconnect-names = "qup-core",
						     "qup-config";
				status = "disabled";
			};

			i2c4: i2c@4a90000 {
				compatible = "qcom,geni-i2c";
				reg = <0x0 0x04a90000 0x0 0x4000>;
				clock-names = "se";
				clocks = <&gcc GCC_QUPV3_WRAP0_S4_CLK>;
				pinctrl-names = "default";
				pinctrl-0 = <&qup_i2c4_default>;
				interrupts = <GIC_SPI 331 IRQ_TYPE_LEVEL_HIGH>;
				dmas = <&gpi_dma0 0 4 QCOM_GPI_I2C>,
				       <&gpi_dma0 1 4 QCOM_GPI_I2C>;
				dma-names = "tx", "rx";
				interconnects = <&clk_virt MASTER_QUP_CORE_0 RPM_ALWAYS_TAG
						 &clk_virt SLAVE_QUP_CORE_0 RPM_ALWAYS_TAG>,
						<&bimc MASTER_AMPSS_M0 RPM_ALWAYS_TAG
						 &config_noc SLAVE_QUP_0 RPM_ALWAYS_TAG>,
						<&system_noc MASTER_QUP_0 RPM_ALWAYS_TAG
						 &bimc SLAVE_EBI_CH0 RPM_ALWAYS_TAG>;
				interconnect-names = "qup-core",
						     "qup-config",
						     "qup-memory";
				#address-cells = <1>;
				#size-cells = <0>;
				status = "disabled";
			};

			spi4: spi@4a90000 {
				compatible = "qcom,geni-spi";
				reg = <0x0 0x04a90000 0x0 0x4000>;
				clock-names = "se";
				clocks = <&gcc GCC_QUPV3_WRAP0_S4_CLK>;
				pinctrl-names = "default";
				pinctrl-0 = <&qup_spi4_default>;
				interrupts = <GIC_SPI 331 IRQ_TYPE_LEVEL_HIGH>;
				dmas = <&gpi_dma0 0 4 QCOM_GPI_SPI>,
				       <&gpi_dma0 1 4 QCOM_GPI_SPI>;
				dma-names = "tx", "rx";
				interconnects = <&clk_virt MASTER_QUP_CORE_0 RPM_ALWAYS_TAG
						 &clk_virt SLAVE_QUP_CORE_0 RPM_ALWAYS_TAG>,
						<&bimc MASTER_AMPSS_M0 RPM_ALWAYS_TAG
						 &config_noc SLAVE_QUP_0 RPM_ALWAYS_TAG>,
						<&system_noc MASTER_QUP_0 RPM_ALWAYS_TAG
						 &bimc SLAVE_EBI_CH0 RPM_ALWAYS_TAG>;
				interconnect-names = "qup-core",
						     "qup-config",
						     "qup-memory";
				#address-cells = <1>;
				#size-cells = <0>;
				status = "disabled";
			};

			uart4: serial@4a90000 {
				compatible = "qcom,geni-debug-uart";
				reg = <0x0 0x04a90000 0x0 0x4000>;
				clock-names = "se";
				clocks = <&gcc GCC_QUPV3_WRAP0_S4_CLK>;
				interrupts = <GIC_SPI 331 IRQ_TYPE_LEVEL_HIGH>;
				interconnects = <&clk_virt MASTER_QUP_CORE_0 RPM_ALWAYS_TAG
						 &clk_virt SLAVE_QUP_CORE_0 RPM_ALWAYS_TAG>,
						<&bimc MASTER_AMPSS_M0 RPM_ALWAYS_TAG
						 &config_noc SLAVE_QUP_0 RPM_ALWAYS_TAG>;
				interconnect-names = "qup-core",
						     "qup-config";
				status = "disabled";
			};

			i2c5: i2c@4a94000 {
				compatible = "qcom,geni-i2c";
				reg = <0x0 0x04a94000 0x0 0x4000>;
				clock-names = "se";
				clocks = <&gcc GCC_QUPV3_WRAP0_S5_CLK>;
				pinctrl-names = "default";
				pinctrl-0 = <&qup_i2c5_default>;
				interrupts = <GIC_SPI 332 IRQ_TYPE_LEVEL_HIGH>;
				dmas = <&gpi_dma0 0 5 QCOM_GPI_I2C>,
				       <&gpi_dma0 1 5 QCOM_GPI_I2C>;
				dma-names = "tx", "rx";
				//interconnects = <&clk_virt MASTER_QUP_CORE_0 RPM_ALWAYS_TAG
				//		 &clk_virt SLAVE_QUP_CORE_0 RPM_ALWAYS_TAG>,
				//		<&bimc MASTER_AMPSS_M0 RPM_ALWAYS_TAG
				//		 &config_noc SLAVE_QUP_0 RPM_ALWAYS_TAG>,
				//		<&system_noc MASTER_QUP_0 RPM_ALWAYS_TAG
				//		 &bimc SLAVE_EBI_CH0 RPM_ALWAYS_TAG>;
				//interconnect-names = "qup-core",
				//		     "qup-config",
				//		     "qup-memory";
				#address-cells = <1>;
				#size-cells = <0>;
				status = "disabled";
			};

			spi5: spi@4a94000 {
				compatible = "qcom,geni-spi";
				reg = <0x0 0x04a94000 0x0 0x4000>;
				clock-names = "se";
				clocks = <&gcc GCC_QUPV3_WRAP0_S5_CLK>;
				pinctrl-names = "default";
				pinctrl-0 = <&qup_spi5_default>;
				interrupts = <GIC_SPI 332 IRQ_TYPE_LEVEL_HIGH>;
				dmas = <&gpi_dma0 0 5 QCOM_GPI_SPI>,
				       <&gpi_dma0 1 5 QCOM_GPI_SPI>;
				dma-names = "tx", "rx";
				interconnects = <&clk_virt MASTER_QUP_CORE_0 RPM_ALWAYS_TAG
						 &clk_virt SLAVE_QUP_CORE_0 RPM_ALWAYS_TAG>,
						<&bimc MASTER_AMPSS_M0 RPM_ALWAYS_TAG
						 &config_noc SLAVE_QUP_0 RPM_ALWAYS_TAG>,
						<&system_noc MASTER_QUP_0 RPM_ALWAYS_TAG
						 &bimc SLAVE_EBI_CH0 RPM_ALWAYS_TAG>;
				interconnect-names = "qup-core",
						     "qup-config",
						     "qup-memory";
				#address-cells = <1>;
				#size-cells = <0>;
				status = "disabled";
			};
		};

		usb: usb@4ef8800 {
			compatible = "qcom,sm6115-dwc3", "qcom,dwc3";
			reg = <0x0 0x04ef8800 0x0 0x400>;
			#address-cells = <2>;
			#size-cells = <2>;
			ranges;

			clocks = <&gcc GCC_CFG_NOC_USB3_PRIM_AXI_CLK>,
				 <&gcc GCC_USB30_PRIM_MASTER_CLK>,
				 <&gcc GCC_SYS_NOC_USB3_PRIM_AXI_CLK>,
				 <&gcc GCC_USB30_PRIM_SLEEP_CLK>,
				 <&gcc GCC_USB30_PRIM_MOCK_UTMI_CLK>,
				 <&gcc GCC_USB3_PRIM_CLKREF_CLK>;
			clock-names = "cfg_noc", "core", "iface", "sleep", "mock_utmi", "xo";

			assigned-clocks = <&gcc GCC_USB30_PRIM_MOCK_UTMI_CLK>,
					  <&gcc GCC_USB30_PRIM_MASTER_CLK>;
			assigned-clock-rates = <19200000>, <66666667>;

			interrupts = <GIC_SPI 302 IRQ_TYPE_LEVEL_HIGH>,
				     <GIC_SPI 260 IRQ_TYPE_LEVEL_HIGH>,
				     <GIC_SPI 254 IRQ_TYPE_LEVEL_HIGH>,
				     <GIC_SPI 422 IRQ_TYPE_LEVEL_HIGH>;
			interrupt-names = "pwr_event",
					  "qusb2_phy",
					  "hs_phy_irq",
					  "ss_phy_irq";

			resets = <&gcc GCC_USB30_PRIM_BCR>;
			power-domains = <&gcc GCC_USB30_PRIM_GDSC>;
			 /* TODO: USB<->IPA path */
			interconnects = <&system_noc MASTER_USB3 RPM_ALWAYS_TAG
					 &bimc SLAVE_EBI_CH0 RPM_ALWAYS_TAG>,
					<&bimc MASTER_AMPSS_M0 RPM_ALWAYS_TAG
					 &config_noc SLAVE_USB3 RPM_ALWAYS_TAG>;
			interconnect-names = "usb-ddr",
					     "apps-usb";

			status = "disabled";

			usb_dwc3: usb@4e00000 {
				compatible = "snps,dwc3";
				reg = <0x0 0x04e00000 0x0 0xcd00>;
				interrupts = <GIC_SPI 255 IRQ_TYPE_LEVEL_HIGH>;
				phys = <&usb_hsphy>, <&usb_qmpphy>;
				phy-names = "usb2-phy", "usb3-phy";
				iommus = <&apps_smmu 0x120 0x0>;
				snps,dis_u2_susphy_quirk;
				snps,dis_enblslpm_quirk;
				snps,has-lpm-erratum;
				snps,hird-threshold = /bits/ 8 <0x10>;
				snps,usb3_lpm_capable;
				snps,parkmode-disable-ss-quirk;

				usb-role-switch;

				ports {
					#address-cells = <1>;
					#size-cells = <0>;

					port@0 {
						reg = <0>;

						usb_dwc3_hs: endpoint {
						};
					};

					port@1 {
						reg = <1>;

						usb_dwc3_ss: endpoint {
							remote-endpoint = <&usb_qmpphy_usb_ss_in>;
						};
					};
				};
			};
		};

		gpu: gpu@5900000 {
			compatible = "qcom,adreno-610.0", "qcom,adreno";
			reg = <0x0 0x05900000 0x0 0x40000>;
			reg-names = "kgsl_3d0_reg_memory";

			/* There's no (real) GMU, so we have to handle quite a bunch of clocks! */
			clocks = <&gpucc GPU_CC_GX_GFX3D_CLK>,
				 <&gpucc GPU_CC_AHB_CLK>,
				 <&gcc GCC_BIMC_GPU_AXI_CLK>,
				 <&gcc GCC_GPU_MEMNOC_GFX_CLK>,
				 <&gpucc GPU_CC_CX_GMU_CLK>,
				 <&gpucc GPU_CC_CXO_CLK>;
			clock-names = "core",
				      "iface",
				      "mem_iface",
				      "alt_mem_iface",
				      "gmu",
				      "xo";

			interrupts = <GIC_SPI 177 IRQ_TYPE_LEVEL_HIGH>;

			iommus = <&adreno_smmu 0 1>,
				 <&adreno_smmu 2 0>;

			interconnects = <&bimc MASTER_GRAPHICS_3D RPM_ALWAYS_TAG
					 &bimc SLAVE_EBI_CH0 RPM_ALWAYS_TAG>;
			interconnect-names = "gfx-mem";

			operating-points-v2 = <&gpu_opp_table>;
			power-domains = <&rpmpd SM6115_VDDCX>;
			qcom,gmu = <&gmu_wrapper>;

			nvmem-cells = <&gpu_speed_bin>;
			nvmem-cell-names = "speed_bin";
			#cooling-cells = <2>;

			status = "disabled";

			zap-shader {
				memory-region = <&pil_gpu_mem>;
			};

			gpu_opp_table: opp-table {
				compatible = "operating-points-v2";

				/*
				 * khaje's own table, per khaje-gpu.dtsi. The
				 * 745/820/900/950/980 MHz entries that used to be
				 * here are bengal's (bengal-gpu.dtsi) and appear
				 * nowhere in khaje's: khaje-gpu.dtsi deletes the
				 * inherited qcom,gpu-pwrlevel-bins outright and
				 * defines 320/465/600/785/1025/1114.8/1260 only.
				 */

				opp-320000000 {
					opp-hz = /bits/ 64 <320000000>;
					opp-peak-kBps = <4273437>;
					required-opps = <&rpmpd_opp_low_svs>;
					opp-supported-hw = <0x1f>;
				};

				opp-465000000 {
					opp-hz = /bits/ 64 <465000000>;
					opp-peak-kBps = <6000000>;
					required-opps = <&rpmpd_opp_svs>;
					opp-supported-hw = <0x1f>;
				};

				opp-600000000 {
					opp-hz = /bits/ 64 <600000000>;
					opp-peak-kBps = <7945312>;
					required-opps = <&rpmpd_opp_svs_plus>;
					opp-supported-hw = <0x1f>;
				};

				opp-785000000 {
					opp-hz = /bits/ 64 <785000000>;
					opp-peak-kBps = <12148437>;
					required-opps = <&rpmpd_opp_nom>;
					opp-supported-hw = <0xf>;
				};

				opp-1025000000 {
					opp-hz = /bits/ 64 <1025000000>;
					opp-peak-kBps = <14093750>;
					required-opps = <&rpmpd_opp_turbo>;
					opp-supported-hw = <0x7>;
				};

				opp-1114800000 {
					opp-hz = /bits/ 64 <1114800000>;
					opp-peak-kBps = <16343750>;
					required-opps = <&rpmpd_opp_turbo_plus>;
					opp-supported-hw = <0x3>;
				};
			};
		};

		gmu_wrapper: gmu@596a000 {
			compatible = "qcom,adreno-gmu-wrapper";
			reg = <0x0 0x0596a000 0x0 0x30000>;
			reg-names = "gmu";
			power-domains = <&gpucc GPU_CX_GDSC>,
					<&gpucc GPU_GX_GDSC>;
			power-domain-names = "cx", "gx";
		};

		gpucc: clock-controller@5990000 {
			compatible = "qcom,sm6225-gpucc";
			reg = <0x0 0x05990000 0x0 0x9000>;
			clocks = <&rpmcc RPM_SMD_XO_CLK_SRC>,
				 <&gcc GCC_GPU_GPLL0_CLK_SRC>,
				 <&gcc GCC_GPU_GPLL0_DIV_CLK_SRC>;
			#clock-cells = <1>;
			#reset-cells = <1>;
			#power-domain-cells = <1>;
		};

		adreno_smmu: iommu@59a0000 {
			compatible = "qcom,sm6115-smmu-500", "qcom,adreno-smmu",
				     "qcom,smmu-500", "arm,mmu-500";
			reg = <0x0 0x059a0000 0x0 0x10000>;
			#iommu-cells = <2>;
			#global-interrupts = <1>;
			interrupts = <GIC_SPI 163 IRQ_TYPE_LEVEL_HIGH>,
				     <GIC_SPI 167 IRQ_TYPE_LEVEL_HIGH>,
				     <GIC_SPI 168 IRQ_TYPE_LEVEL_HIGH>,
				     <GIC_SPI 169 IRQ_TYPE_LEVEL_HIGH>,
				     <GIC_SPI 170 IRQ_TYPE_LEVEL_HIGH>,
				     <GIC_SPI 171 IRQ_TYPE_LEVEL_HIGH>,
				     <GIC_SPI 172 IRQ_TYPE_LEVEL_HIGH>,
				     <GIC_SPI 173 IRQ_TYPE_LEVEL_HIGH>,
				     <GIC_SPI 174 IRQ_TYPE_LEVEL_HIGH>;

			clocks = <&gcc GCC_GPU_MEMNOC_GFX_CLK>,
				 <&gpucc GPU_CC_HLOS1_VOTE_GPU_SMMU_CLK>,
				 <&gcc GCC_GPU_SNOC_DVM_GFX_CLK>,
				 <&gpucc GPU_CC_AHB_CLK>;
			clock-names = "mem",
				      "hlos",
				      "iface",
				      "ahb";

			power-domains = <&gpucc GPU_CX_GDSC>;
			status = "disabled";
		};

		mdss: display-subsystem@5e00000 {
			compatible = "qcom,sm6225-mdss";
			reg = <0x0 0x05e00000 0x0 0x1000>;
			reg-names = "mdss";

			resets = <&dispcc 0>;
			power-domains = <&dispcc MDSS_GDSC>;

			clocks = <&gcc GCC_DISP_AHB_CLK>,
				 <&gcc GCC_DISP_HF_AXI_CLK>,
				 <&dispcc DISP_CC_MDSS_MDP_CLK>;

			interrupts = <GIC_SPI 186 IRQ_TYPE_LEVEL_HIGH>;
			interrupt-controller;
			#interrupt-cells = <1>;

			interconnects = <&mmrt_virt MASTER_MDP_PORT0 RPM_ALWAYS_TAG
					 &bimc SLAVE_EBI_CH0 RPM_ALWAYS_TAG>,
					<&bimc MASTER_AMPSS_M0 RPM_ALWAYS_TAG
					 &config_noc SLAVE_DISPLAY_CFG RPM_ALWAYS_TAG>;
			interconnect-names = "mdp0-mem",
					     "cpu-cfg";
			iommus = <&apps_smmu 0x420 0x2>,
				 <&apps_smmu 0x421 0x0>;

			#address-cells = <2>;
			#size-cells = <2>;
			ranges;

			status = "disabled";

			mdp: display-controller@5e01000 {
				compatible = "qcom,sm6225-dpu";
				reg = <0x0 0x05e01000 0x0 0x8f000>,
				      <0x0 0x05eb0000 0x0 0x3000>;
				reg-names = "mdp", "vbif";

				clocks = <&gcc GCC_DISP_HF_AXI_CLK>,
					 <&dispcc DISP_CC_MDSS_AHB_CLK>,
					 <&dispcc DISP_CC_MDSS_ROT_CLK>,
					 <&dispcc DISP_CC_MDSS_MDP_LUT_CLK>,
					 <&dispcc DISP_CC_MDSS_MDP_CLK>,
					 <&dispcc DISP_CC_MDSS_VSYNC_CLK>,
					 <&gcc GCC_DISP_THROTTLE_CORE_CLK>;
				clock-names = "bus",
					      "iface",
					      "rot",
					      "lut",
					      "core",
					      "vsync",
					      "throttle";

				assigned-clocks = <&dispcc DISP_CC_MDSS_VSYNC_CLK>;
				assigned-clock-rates = <19200000>;

				operating-points-v2 = <&mdp_opp_table>;
				power-domains = <&rpmpd SM6115_VDDCX>;

				interrupt-parent = <&mdss>;
				interrupts = <0>;

				ports {
					#address-cells = <1>;
					#size-cells = <0>;

					port@0 {
						reg = <0>;
						dpu_intf1_out: endpoint {
							remote-endpoint = <&mdss_dsi0_in>;
						};
					};
				};

				mdp_opp_table: opp-table {
					compatible = "operating-points-v2";

					opp-19200000 {
						opp-hz = /bits/ 64 <19200000>;
						required-opps = <&rpmpd_opp_min_svs>;
					};

					opp-200000000 {
						opp-hz = /bits/ 64 <200000000>;
						required-opps = <&rpmpd_opp_low_svs>;
					};

					opp-300000000 {
						opp-hz = /bits/ 64 <300000000>;
						required-opps = <&rpmpd_opp_svs>;
					};

					opp-383000000 {
						opp-hz = /bits/ 64 <383000000>;
						required-opps = <&rpmpd_opp_svs_plus>;
					};

					opp-470000000 {
						opp-hz = /bits/ 64 <470000000>;
						required-opps = <&rpmpd_opp_nom>;
					};

					opp-560000000 {
						opp-hz = /bits/ 64 <560000000>;
						required-opps = <&rpmpd_opp_turbo>;
					};
				};
			};

			mdss_dsi0: dsi@5e94000 {
				compatible = "qcom,sm6115-dsi-ctrl", "qcom,mdss-dsi-ctrl";
				reg = <0x0 0x05e94000 0x0 0x400>;
				reg-names = "dsi_ctrl";

				interrupt-parent = <&mdss>;
				interrupts = <4>;

				clocks = <&dispcc DISP_CC_MDSS_BYTE0_CLK>,
					 <&dispcc DISP_CC_MDSS_BYTE0_INTF_CLK>,
					 <&dispcc DISP_CC_MDSS_PCLK0_CLK>,
					 <&dispcc DISP_CC_MDSS_ESC0_CLK>,
					 <&dispcc DISP_CC_MDSS_AHB_CLK>,
					 <&gcc GCC_DISP_HF_AXI_CLK>;
				clock-names = "byte",
					      "byte_intf",
					      "pixel",
					      "core",
					      "iface",
					      "bus";

				assigned-clocks = <&dispcc DISP_CC_MDSS_BYTE0_CLK_SRC>,
						  <&dispcc DISP_CC_MDSS_PCLK0_CLK_SRC>;
				assigned-clock-parents = <&mdss_dsi0_phy 0>, <&mdss_dsi0_phy 1>;

				operating-points-v2 = <&dsi_opp_table>;
				power-domains = <&rpmpd SM6115_VDDCX>;
				phys = <&mdss_dsi0_phy>;

				#address-cells = <1>;
				#size-cells = <0>;

				status = "disabled";

				ports {
					#address-cells = <1>;
					#size-cells = <0>;

					port@0 {
						reg = <0>;
						mdss_dsi0_in: endpoint {
							remote-endpoint = <&dpu_intf1_out>;
						};
					};

					port@1 {
						reg = <1>;
						mdss_dsi0_out: endpoint {
						};
					};
				};

				dsi_opp_table: opp-table {
					compatible = "operating-points-v2";

					opp-187500000 {
						opp-hz = /bits/ 64 <187500000>;
						required-opps = <&rpmpd_opp_low_svs>;
					};

					opp-300000000 {
						opp-hz = /bits/ 64 <300000000>;
						required-opps = <&rpmpd_opp_svs>;
					};

					opp-358000000 {
						opp-hz = /bits/ 64 <358000000>;
						required-opps = <&rpmpd_opp_svs_plus>;
					};
				};
			};

			mdss_dsi0_phy: phy@5e94400 {
				compatible = "qcom,sm6375-dsi-phy-7nm";
				reg = <0x0 0x05e94400 0x0 0x200>,
				      <0x0 0x05e94600 0x0 0x280>,
				      <0x0 0x05e94900 0x0 0x264>;
				reg-names = "dsi_phy",
					    "dsi_phy_lane",
					    "dsi_pll";

				#clock-cells = <1>;
				#phy-cells = <0>;

				clocks = <&dispcc DISP_CC_MDSS_AHB_CLK>,
					 <&rpmcc RPM_SMD_XO_CLK_SRC>;
				clock-names = "iface", "ref";

				status = "disabled";
			};
		};

		dispcc: clock-controller@5f00000 {
			compatible = "qcom,sm6225-dispcc";
			reg = <0x0 0x05f00000 0x0 0x20000>;
			clocks = <&rpmcc RPM_SMD_XO_CLK_SRC>,
				 <&gcc GCC_DISP_GPLL0_DIV_CLK_SRC>,
				 <&mdss_dsi0_phy 0>,
				 <&mdss_dsi0_phy 1>;
			#clock-cells = <1>;
			#reset-cells = <1>;
			#power-domain-cells = <1>;
		};

		imem: sram@c100000 {
			compatible = "qcom,sm6115-imem", "mmio-sram";
			reg = <0x0 0xc100000 0x0 0x26000>;
			ranges = <0x0 0x0 0xc100000 0x26000>;

			#address-cells = <1>;
			#size-cells = <1>;

			mem_dump_table@10 {
				compatible = "qcom,msm-imem-mem_dump_table";
				reg = <0x10 0x8>;
			};

			restart_reason@65c {
				compatible = "qcom,msm-imem-restart_reason";
				reg = <0x65c 0x4>;
			};

			dload_type@1c {
				compatible = "qcom,msm-imem-dload-type";
				reg = <0x1c 0x4>;
			};

			boot_stats@6b0 {
				compatible = "qcom,msm-imem-boot_stats";
				reg = <0x6b0 0x20>;
			};

			kaslr_offset@6d0 {
				compatible = "qcom,msm-imem-kaslr_offset";
				reg = <0x6d0 0xc>;
			};

			pil@94c {
				compatible = "qcom,pil-info";
				reg = <0x94c 0xc8>;
			};

			diag_dload@c8 {
				compatible = "qcom,msm-imem-diag-dload";
				reg = <0xc8 0xc8>;
			};

			ipa_modem_tables: modem-tables-sram@23000 {
				reg = <0x23000 0x2000>;
			};
		};

		ipa: ipa@5800000 {
			compatible = "qcom,sc7180-ipa";

			reg = <0x0 0x05840000 0x0 0x7000>,
			      <0x0 0x05847000 0x0 0x2000>,
			      <0x0 0x05804000 0x0 0x28000>;
			reg-names = "ipa-reg", "ipa-shared", "gsi";

			iommus = <&apps_smmu 0x140 0x0>;

			interrupts-extended = <&intc GIC_SPI 257 IRQ_TYPE_EDGE_RISING>,
					      <&intc GIC_SPI 259 IRQ_TYPE_LEVEL_HIGH>,
					      <&ipa_smp2p_in 0 IRQ_TYPE_EDGE_RISING>,
					      <&ipa_smp2p_in 1 IRQ_TYPE_EDGE_RISING>;
			interrupt-names = "ipa", "gsi",
					  "ipa-clock-query", "ipa-setup-ready";

			clocks = <&rpmcc RPM_SMD_IPA_CLK>;
			clock-names = "core";

			interconnects = <&system_noc MASTER_IPA RPM_ALWAYS_TAG
					&bimc SLAVE_EBI_CH0 RPM_ALWAYS_TAG>,
					<&system_noc MASTER_IPA RPM_ALWAYS_TAG
					&system_noc SLAVE_OCIMEM RPM_ALWAYS_TAG>,
					<&bimc MASTER_AMPSS_M0 RPM_ALWAYS_TAG
					&config_noc SLAVE_IPA_CFG RPM_ALWAYS_TAG>;
			interconnect-names = "memory", "imem", "config";

			qcom,smem-states = <&ipa_smp2p_out 0>,
					   <&ipa_smp2p_out 1>;
			qcom,smem-state-names = "ipa-clock-enabled-valid",
						"ipa-clock-enabled";

			sram = <&ipa_modem_tables>;

			qcom,gsi-loader = "self";
			memory-region = <&pil_ipa_fw_mem>;

			status = "disabled";
		};

		remoteproc_mpss: remoteproc@6080000 {
			compatible = "qcom,sm6115-mpss-pas";
			reg = <0x0 0x06080000 0x0 0x10000>;

			interrupts-extended = <&intc GIC_SPI 307 IRQ_TYPE_EDGE_RISING>,
					      <&modem_smp2p_in 0 IRQ_TYPE_EDGE_RISING>,
					      <&modem_smp2p_in 1 IRQ_TYPE_EDGE_RISING>,
					      <&modem_smp2p_in 2 IRQ_TYPE_EDGE_RISING>,
					      <&modem_smp2p_in 3 IRQ_TYPE_EDGE_RISING>,
					      <&modem_smp2p_in 7 IRQ_TYPE_EDGE_RISING>;
			interrupt-names = "wdog", "fatal", "ready", "handover",
					  "stop-ack", "shutdown-ack";

			clocks = <&rpmcc RPM_SMD_XO_CLK_SRC>;
			clock-names = "xo";

			power-domains = <&rpmpd SM6115_VDDCX>;

			memory-region = <&pil_modem_mem>;

			qcom,smem-states = <&modem_smp2p_out 0>;
			qcom,smem-state-names = "stop";

			status = "disabled";

			glink-edge {
				interrupts = <GIC_SPI 68 IRQ_TYPE_EDGE_RISING>;
				label = "mpss";
				qcom,remote-pid = <1>;
				mboxes = <&apcs_glb 12>;
			};
		};

		stm@8002000 {
			compatible = "arm,coresight-stm", "arm,primecell";
			reg = <0x0 0x08002000 0x0 0x1000>,
			      <0x0 0x0e280000 0x0 0x180000>;
			reg-names = "stm-base", "stm-stimulus-base";

			clocks = <&rpmcc RPM_SMD_QDSS_CLK>;
			clock-names = "apb_pclk";

			status = "disabled";

			out-ports {
				port {
					stm_out: endpoint {
						remote-endpoint = <&funnel_in0_in>;
					};
				};
			};
		};

		cti0: cti@8010000 {
			compatible = "arm,coresight-cti", "arm,primecell";
			reg = <0x0 0x08010000 0x0 0x1000>;

			clocks = <&rpmcc RPM_SMD_QDSS_CLK>;
			clock-names = "apb_pclk";

			status = "disabled";
		};

		cti1: cti@8011000 {
			compatible = "arm,coresight-cti", "arm,primecell";
			reg = <0x0 0x08011000 0x0 0x1000>;

			clocks = <&rpmcc RPM_SMD_QDSS_CLK>;
			clock-names = "apb_pclk";

			status = "disabled";
		};

		cti2: cti@8012000 {
			compatible = "arm,coresight-cti", "arm,primecell";
			reg = <0x0 0x08012000 0x0 0x1000>;

			clocks = <&rpmcc RPM_SMD_QDSS_CLK>;
			clock-names = "apb_pclk";

			status = "disabled";
		};

		cti3: cti@8013000 {
			compatible = "arm,coresight-cti", "arm,primecell";
			reg = <0x0 0x08013000 0x0 0x1000>;

			clocks = <&rpmcc RPM_SMD_QDSS_CLK>;
			clock-names = "apb_pclk";

			status = "disabled";
		};

		cti4: cti@8014000 {
			compatible = "arm,coresight-cti", "arm,primecell";
			reg = <0x0 0x08014000 0x0 0x1000>;

			clocks = <&rpmcc RPM_SMD_QDSS_CLK>;
			clock-names = "apb_pclk";

			status = "disabled";
		};

		cti5: cti@8015000 {
			compatible = "arm,coresight-cti", "arm,primecell";
			reg = <0x0 0x08015000 0x0 0x1000>;

			clocks = <&rpmcc RPM_SMD_QDSS_CLK>;
			clock-names = "apb_pclk";

			status = "disabled";
		};

		cti6: cti@8016000 {
			compatible = "arm,coresight-cti", "arm,primecell";
			reg = <0x0 0x08016000 0x0 0x1000>;

			clocks = <&rpmcc RPM_SMD_QDSS_CLK>;
			clock-names = "apb_pclk";

			status = "disabled";
		};

		cti7: cti@8017000 {
			compatible = "arm,coresight-cti", "arm,primecell";
			reg = <0x0 0x08017000 0x0 0x1000>;

			clocks = <&rpmcc RPM_SMD_QDSS_CLK>;
			clock-names = "apb_pclk";

			status = "disabled";
		};

		cti8: cti@8018000 {
			compatible = "arm,coresight-cti", "arm,primecell";
			reg = <0x0 0x08018000 0x0 0x1000>;

			clocks = <&rpmcc RPM_SMD_QDSS_CLK>;
			clock-names = "apb_pclk";

			status = "disabled";
		};

		cti9: cti@8019000 {
			compatible = "arm,coresight-cti", "arm,primecell";
			reg = <0x0 0x08019000 0x0 0x1000>;

			clocks = <&rpmcc RPM_SMD_QDSS_CLK>;
			clock-names = "apb_pclk";

			status = "disabled";
		};

		cti10: cti@801a000 {
			compatible = "arm,coresight-cti", "arm,primecell";
			reg = <0x0 0x0801a000 0x0 0x1000>;

			clocks = <&rpmcc RPM_SMD_QDSS_CLK>;
			clock-names = "apb_pclk";

			status = "disabled";
		};

		cti11: cti@801b000 {
			compatible = "arm,coresight-cti", "arm,primecell";
			reg = <0x0 0x0801b000 0x0 0x1000>;

			clocks = <&rpmcc RPM_SMD_QDSS_CLK>;
			clock-names = "apb_pclk";

			status = "disabled";
		};

		cti12: cti@801c000 {
			compatible = "arm,coresight-cti", "arm,primecell";
			reg = <0x0 0x0801c000 0x0 0x1000>;

			clocks = <&rpmcc RPM_SMD_QDSS_CLK>;
			clock-names = "apb_pclk";

			status = "disabled";
		};

		cti13: cti@801d000 {
			compatible = "arm,coresight-cti", "arm,primecell";
			reg = <0x0 0x0801d000 0x0 0x1000>;

			clocks = <&rpmcc RPM_SMD_QDSS_CLK>;
			clock-names = "apb_pclk";

			status = "disabled";
		};

		cti14: cti@801e000 {
			compatible = "arm,coresight-cti", "arm,primecell";
			reg = <0x0 0x0801e000 0x0 0x1000>;

			clocks = <&rpmcc RPM_SMD_QDSS_CLK>;
			clock-names = "apb_pclk";

			status = "disabled";
		};

		cti15: cti@801f000 {
			compatible = "arm,coresight-cti", "arm,primecell";
			reg = <0x0 0x0801f000 0x0 0x1000>;

			clocks = <&rpmcc RPM_SMD_QDSS_CLK>;
			clock-names = "apb_pclk";

			status = "disabled";
		};

		replicator@8046000 {
			compatible = "arm,coresight-dynamic-replicator", "arm,primecell";
			reg = <0x0 0x08046000 0x0 0x1000>;

			clocks = <&rpmcc RPM_SMD_QDSS_CLK>;
			clock-names = "apb_pclk";

			status = "disabled";

			out-ports {
				port {
					replicator_out: endpoint {
						remote-endpoint = <&etr_in>;
					};
				};
			};

			in-ports {
				port {
					replicator_in: endpoint {
						remote-endpoint = <&etf_out>;
					};
				};
			};
		};

		etf@8047000 {
			compatible = "arm,coresight-tmc", "arm,primecell";
			reg = <0x0 0x08047000 0x0 0x1000>;

			clocks = <&rpmcc RPM_SMD_QDSS_CLK>;
			clock-names = "apb_pclk";

			status = "disabled";

			in-ports {
				port {
					etf_in: endpoint {
						remote-endpoint = <&merge_funnel_out>;
					};
				};
			};

			out-ports {
				port {
					etf_out: endpoint {
						remote-endpoint = <&replicator_in>;
					};
				};
			};
		};

		etr@8048000 {
			compatible = "arm,coresight-tmc", "arm,primecell";
			reg = <0x0 0x08048000 0x0 0x1000>;

			clocks = <&rpmcc RPM_SMD_QDSS_CLK>;
			clock-names = "apb_pclk";

			status = "disabled";

			in-ports {
				port {
					etr_in: endpoint {
						remote-endpoint = <&replicator_out>;
					};
				};
			};
		};

		funnel@8041000 {
			compatible = "arm,coresight-dynamic-funnel", "arm,primecell";
			reg = <0x0 0x08041000 0x0 0x1000>;

			clocks = <&rpmcc RPM_SMD_QDSS_CLK>;
			clock-names = "apb_pclk";

			status = "disabled";

			out-ports {
				port {
					funnel_in0_out: endpoint {
						remote-endpoint = <&merge_funnel_in0>;
					};
				};
			};

			in-ports {
				port {
					funnel_in0_in: endpoint {
						remote-endpoint = <&stm_out>;
					};
				};
			};
		};

		funnel@8042000 {
			compatible = "arm,coresight-dynamic-funnel", "arm,primecell";
			reg = <0x0 0x08042000 0x0 0x1000>;

			clocks = <&rpmcc RPM_SMD_QDSS_CLK>;
			clock-names = "apb_pclk";

			status = "disabled";

			out-ports {
				port {
					funnel_in1_out: endpoint {
						remote-endpoint = <&merge_funnel_in1>;
					};
				};
			};

			in-ports {
				port {
					funnel_in1_in: endpoint {
						remote-endpoint = <&funnel_apss1_out>;
					};
				};
			};
		};

		funnel@8045000 {
			compatible = "arm,coresight-dynamic-funnel", "arm,primecell";
			reg = <0x0 0x08045000 0x0 0x1000>;

			clocks = <&rpmcc RPM_SMD_QDSS_CLK>;
			clock-names = "apb_pclk";

			status = "disabled";

			out-ports {
				port {
					merge_funnel_out: endpoint {
						remote-endpoint = <&etf_in>;
					};
				};
			};

			in-ports {
				#address-cells = <1>;
				#size-cells = <0>;

				port@0 {
					reg = <0>;
					merge_funnel_in0: endpoint {
						remote-endpoint = <&funnel_in0_out>;
					};
				};

				port@1 {
					reg = <1>;
					merge_funnel_in1: endpoint {
						remote-endpoint = <&funnel_in1_out>;
					};
				};
			};
		};

		etm@9040000 {
			compatible = "arm,coresight-etm4x", "arm,primecell";
			reg = <0x0 0x09040000 0x0 0x1000>;

			clocks = <&rpmcc RPM_SMD_QDSS_CLK>;
			clock-names = "apb_pclk";
			arm,coresight-loses-context-with-cpu;

			cpu = <&cpu0>;

			status = "disabled";

			out-ports {
				port {
					etm0_out: endpoint {
						remote-endpoint = <&funnel_apss0_in0>;
					};
				};
			};
		};

		etm@9140000 {
			compatible = "arm,coresight-etm4x", "arm,primecell";
			reg = <0x0 0x09140000 0x0 0x1000>;

			clocks = <&rpmcc RPM_SMD_QDSS_CLK>;
			clock-names = "apb_pclk";
			arm,coresight-loses-context-with-cpu;

			cpu = <&cpu1>;

			status = "disabled";

			out-ports {
				port {
					etm1_out: endpoint {
						remote-endpoint = <&funnel_apss0_in1>;
					};
				};
			};
		};

		etm@9240000 {
			compatible = "arm,coresight-etm4x", "arm,primecell";
			reg = <0x0 0x09240000 0x0 0x1000>;

			clocks = <&rpmcc RPM_SMD_QDSS_CLK>;
			clock-names = "apb_pclk";
			arm,coresight-loses-context-with-cpu;

			cpu = <&cpu2>;

			status = "disabled";

			out-ports {
				port {
					etm2_out: endpoint {
						remote-endpoint = <&funnel_apss0_in2>;
					};
				};
			};
		};

		etm@9340000 {
			compatible = "arm,coresight-etm4x", "arm,primecell";
			reg = <0x0 0x09340000 0x0 0x1000>;

			clocks = <&rpmcc RPM_SMD_QDSS_CLK>;
			clock-names = "apb_pclk";
			arm,coresight-loses-context-with-cpu;

			cpu = <&cpu3>;

			status = "disabled";

			out-ports {
				port {
					etm3_out: endpoint {
						remote-endpoint = <&funnel_apss0_in3>;
					};
				};
			};
		};

		etm@9440000 {
			compatible = "arm,coresight-etm4x", "arm,primecell";
			reg = <0x0 0x09440000 0x0 0x1000>;

			clocks = <&rpmcc RPM_SMD_QDSS_CLK>;
			clock-names = "apb_pclk";
			arm,coresight-loses-context-with-cpu;

			cpu = <&cpu4>;

			status = "disabled";

			out-ports {
				port {
					etm4_out: endpoint {
						remote-endpoint = <&funnel_apss0_in4>;
					};
				};
			};
		};

		etm@9540000 {
			compatible = "arm,coresight-etm4x", "arm,primecell";
			reg = <0x0 0x09540000 0x0 0x1000>;

			clocks = <&rpmcc RPM_SMD_QDSS_CLK>;
			clock-names = "apb_pclk";
			arm,coresight-loses-context-with-cpu;

			cpu = <&cpu5>;

			status = "disabled";

			out-ports {
				port {
					etm5_out: endpoint {
						remote-endpoint = <&funnel_apss0_in5>;
					};
				};
			};
		};

		etm@9640000 {
			compatible = "arm,coresight-etm4x", "arm,primecell";
			reg = <0x0 0x09640000 0x0 0x1000>;

			clocks = <&rpmcc RPM_SMD_QDSS_CLK>;
			clock-names = "apb_pclk";
			arm,coresight-loses-context-with-cpu;

			cpu = <&cpu6>;

			status = "disabled";

			out-ports {
				port {
					etm6_out: endpoint {
						remote-endpoint = <&funnel_apss0_in6>;
					};
				};
			};
		};

		etm@9740000 {
			compatible = "arm,coresight-etm4x", "arm,primecell";
			reg = <0x0 0x09740000 0x0 0x1000>;

			clocks = <&rpmcc RPM_SMD_QDSS_CLK>;
			clock-names = "apb_pclk";
			arm,coresight-loses-context-with-cpu;

			cpu = <&cpu7>;

			status = "disabled";

			out-ports {
				port {
					etm7_out: endpoint {
						remote-endpoint = <&funnel_apss0_in7>;
					};
				};
			};
		};

		funnel@9800000 {
			compatible = "arm,coresight-dynamic-funnel", "arm,primecell";
			reg = <0x0 0x09800000 0x0 0x1000>;

			clocks = <&rpmcc RPM_SMD_QDSS_CLK>;
			clock-names = "apb_pclk";

			status = "disabled";

			out-ports {
				port {
					funnel_apss0_out: endpoint {
						remote-endpoint = <&funnel_apss1_in>;
					};
				};
			};

			in-ports {
				#address-cells = <1>;
				#size-cells = <0>;

				port@0 {
					reg = <0>;
					funnel_apss0_in0: endpoint {
						remote-endpoint = <&etm0_out>;
					};
				};

				port@1 {
					reg = <1>;
					funnel_apss0_in1: endpoint {
						remote-endpoint = <&etm1_out>;
					};
				};

				port@2 {
					reg = <2>;
					funnel_apss0_in2: endpoint {
						remote-endpoint = <&etm2_out>;
					};
				};

				port@3 {
					reg = <3>;
					funnel_apss0_in3: endpoint {
						remote-endpoint = <&etm3_out>;
					};
				};

				port@4 {
					reg = <4>;
					funnel_apss0_in4: endpoint {
						remote-endpoint = <&etm4_out>;
					};
				};

				port@5 {
					reg = <5>;
					funnel_apss0_in5: endpoint {
						remote-endpoint = <&etm5_out>;
					};
				};

				port@6 {
					reg = <6>;
					funnel_apss0_in6: endpoint {
						remote-endpoint = <&etm6_out>;
					};
				};

				port@7 {
					reg = <7>;
					funnel_apss0_in7: endpoint {
						remote-endpoint = <&etm7_out>;
					};
				};
			};
		};

		funnel@9810000 {
			compatible = "arm,coresight-dynamic-funnel", "arm,primecell";
			reg = <0x0 0x09810000 0x0 0x1000>;

			clocks = <&rpmcc RPM_SMD_QDSS_CLK>;
			clock-names = "apb_pclk";

			status = "disabled";

			out-ports {
				port {
					funnel_apss1_out: endpoint {
						remote-endpoint = <&funnel_in1_in>;
					};
				};
			};

			in-ports {
				port {
					funnel_apss1_in: endpoint {
						remote-endpoint = <&funnel_apss0_out>;
					};
				};
			};
		};

		remoteproc_adsp: remoteproc@a400000 {
			compatible = "qcom,sm6115-adsp-pas";
			reg = <0x0 0x0a400000 0x0 0x4040>;

			interrupts-extended = <&intc GIC_SPI 282 IRQ_TYPE_EDGE_RISING>,
					      <&adsp_smp2p_in 0 IRQ_TYPE_EDGE_RISING>,
					      <&adsp_smp2p_in 1 IRQ_TYPE_EDGE_RISING>,
					      <&adsp_smp2p_in 2 IRQ_TYPE_EDGE_RISING>,
					      <&adsp_smp2p_in 3 IRQ_TYPE_EDGE_RISING>;
			interrupt-names = "wdog", "fatal", "ready",
					  "handover", "stop-ack";

			clocks = <&rpmcc RPM_SMD_XO_CLK_SRC>;
			clock-names = "xo";

			power-domains = <&rpmpd SM6115_VDD_LPI_CX>,
					<&rpmpd SM6115_VDD_LPI_MX>;

			memory-region = <&pil_adsp_mem>;

			qcom,smem-states = <&adsp_smp2p_out 0>;
			qcom,smem-state-names = "stop";

			status = "disabled";

			glink-edge {
				interrupts = <GIC_SPI 277 IRQ_TYPE_EDGE_RISING>;
				label = "lpass";
				qcom,remote-pid = <2>;
				mboxes = <&apcs_glb 8>;

				gpr {
					compatible = "qcom,gpr";
					qcom,glink-channels = "adsp_apps";
					qcom,domain = <GPR_DOMAIN_ID_ADSP>;
					qcom,intents = <512 20>;
					#address-cells = <1>;
					#size-cells = <0>;

					q6apm: service@1 {
						compatible = "qcom,q6apm";
						reg = <GPR_APM_MODULE_IID>;
						#sound-dai-cells = <0>;
						qcom,protection-domain = "avs/audio",
									 "msm/adsp/audio_pd";

						q6apmdai: dais {
							compatible = "qcom,q6apm-dais";
							iommus = <&apps_smmu 0x1c1 0x0>;
						};

						q6apmbedai: bedais {
							compatible = "qcom,q6apm-lpass-dais";
							#sound-dai-cells = <1>;
						};
					};

					q6prm: service@2 {
						compatible = "qcom,q6prm";
						reg = <GPR_PRM_MODULE_IID>;
						qcom,protection-domain = "avs/audio",
									 "msm/adsp/audio_pd";

						q6prmcc: clock-controller {
							compatible = "qcom,q6prm-lpass-clocks";
							#clock-cells = <2>;
						};
					};
				};

				fastrpc {
					compatible = "qcom,fastrpc";
					qcom,glink-channels = "fastrpcglink-apps-dsp";
					label = "adsp";
					memory-region = <&adsp_rpc_remote_heap_mem>;
					qcom,vmids = <QCOM_SCM_VMID_LPASS
						      QCOM_SCM_VMID_ADSP_HEAP>;
					qcom,non-secure-domain;
					#address-cells = <1>;
					#size-cells = <0>;

					compute-cb@3 {
						compatible = "qcom,fastrpc-compute-cb";
						reg = <3>;
						iommus = <&apps_smmu 0x01c3 0x0>;
					};

					compute-cb@4 {
						compatible = "qcom,fastrpc-compute-cb";
						reg = <4>;
						iommus = <&apps_smmu 0x01c4 0x0>;
					};

					compute-cb@5 {
						compatible = "qcom,fastrpc-compute-cb";
						reg = <5>;
						iommus = <&apps_smmu 0x01c5 0x0>;
					};

					compute-cb@6 {
						compatible = "qcom,fastrpc-compute-cb";
						reg = <6>;
						iommus = <&apps_smmu 0x01c6 0x0>;
					};

					compute-cb@7 {
						compatible = "qcom,fastrpc-compute-cb";
						reg = <7>;
						iommus = <&apps_smmu 0x01c7 0x0>;
					};
				};
			};
		};

		/*
		 * LPASS digital codec: RX, TX and VA macros and their two
		 * SoundWire masters. The same block as SM6115/QCM2290 (addresses
		 * and interrupts match the stock SM6225 DT); the clocks come from
		 * the DSP's PRM, as the rest of this AudioReach audio does.
		 */
		rxmacro: codec@a600000 {
			compatible = "qcom,sm6115-lpass-rx-macro";
			reg = <0x0 0x0a600000 0x0 0x1000>;

			clocks = <&q6prmcc LPASS_CLK_ID_RX_CORE_MCLK
				  LPASS_CLK_ATTRIBUTE_COUPLE_NO>,
				 <&q6prmcc LPASS_CLK_ID_RX_CORE_NPL_MCLK
				  LPASS_CLK_ATTRIBUTE_COUPLE_NO>,
				 <&q6prmcc LPASS_HW_DCODEC_VOTE
				  LPASS_CLK_ATTRIBUTE_COUPLE_NO>,
				 <&vamacro>;
			clock-names = "mclk",
				      "npl",
				      "dcodec",
				      "fsgen";
			#clock-cells = <0>;
			clock-output-names = "mclk";
			#sound-dai-cells = <1>;

			status = "disabled";
		};

		swr1: soundwire@a610000 {
			compatible = "qcom,soundwire-v1.6.0";
			reg = <0x0 0x0a610000 0x0 0x10000>;
			interrupts = <GIC_SPI 297 IRQ_TYPE_LEVEL_HIGH>;

			clocks = <&rxmacro>;
			clock-names = "iface";

			resets = <&lpass_audiocc 0>;
			reset-names = "swr_audio_cgcr";

			label = "RX";
			qcom,din-ports = <0>;
			qcom,dout-ports = <5>;

			qcom,ports-sinterval-low =	/bits/ 8 <0x03 0x1f 0x1f 0x07 0x00>;
			qcom,ports-offset1 =		/bits/ 8 <0x00 0x00 0x0b 0x01 0x00>;
			qcom,ports-offset2 =		/bits/ 8 <0x00 0x00 0x0b 0x00 0x00>;
			qcom,ports-hstart =		/bits/ 8 <0xff 0x03 0xff 0xff 0xff>;
			qcom,ports-hstop =		/bits/ 8 <0xff 0x06 0xff 0xff 0xff>;
			qcom,ports-word-length =	/bits/ 8 <0x01 0x07 0x04 0xff 0xff>;
			qcom,ports-block-pack-mode =	/bits/ 8 <0xff 0x00 0x01 0xff 0xff>;
			qcom,ports-block-group-count =	/bits/ 8 <0xff 0xff 0xff 0xff 0x00>;
			qcom,ports-lane-control =	/bits/ 8 <0x01 0x00 0x00 0x00 0x00>;

			#sound-dai-cells = <1>;
			#address-cells = <2>;
			#size-cells = <0>;

			status = "disabled";
		};

		txmacro: codec@a620000 {
			compatible = "qcom,sm6115-lpass-tx-macro";
			reg = <0x0 0x0a620000 0x0 0x1000>;

			clocks = <&q6prmcc LPASS_CLK_ID_TX_CORE_MCLK
				  LPASS_CLK_ATTRIBUTE_COUPLE_NO>,
				 <&q6prmcc LPASS_CLK_ID_TX_CORE_NPL_MCLK
				  LPASS_CLK_ATTRIBUTE_COUPLE_NO>,
				 <&q6prmcc LPASS_HW_DCODEC_VOTE
				  LPASS_CLK_ATTRIBUTE_COUPLE_NO>,
				 <&vamacro>;
			clock-names = "mclk",
				      "npl",
				      "dcodec",
				      "fsgen";
			#clock-cells = <0>;
			clock-output-names = "mclk";
			#sound-dai-cells = <1>;

			status = "disabled";
		};

		lpass_audiocc: clock-controller@a6a9000 {
			compatible = "qcom,sm6115-lpassaudiocc";
			reg = <0x0 0x0a6a9000 0x0 0x1000>;
			#reset-cells = <1>;
		};

		vamacro: codec@a730000 {
			compatible = "qcom,sm6115-lpass-va-macro";
			reg = <0x0 0x0a730000 0x0 0x1000>;

			clocks = <&q6prmcc LPASS_CLK_ID_TX_CORE_MCLK
				  LPASS_CLK_ATTRIBUTE_COUPLE_NO>,
				 <&q6prmcc LPASS_HW_DCODEC_VOTE
				  LPASS_CLK_ATTRIBUTE_COUPLE_NO>,
				 <&q6prmcc LPASS_CLK_ID_TX_CORE_NPL_MCLK
				  LPASS_CLK_ATTRIBUTE_COUPLE_NO>;
			clock-names = "mclk",
				      "dcodec",
				      "npl";
			#clock-cells = <0>;
			clock-output-names = "fsgen";
			#sound-dai-cells = <1>;

			status = "disabled";
		};

		swr0: soundwire@a740000 {
			compatible = "qcom,soundwire-v1.6.0";
			reg = <0x0 0x0a740000 0x0 0x10000>;
			interrupts = <GIC_SPI 296 IRQ_TYPE_LEVEL_HIGH>,
				     <GIC_SPI 79 IRQ_TYPE_LEVEL_HIGH>;

			clocks = <&txmacro>;
			clock-names = "iface";

			resets = <&lpasscc 0>;
			reset-names = "swr_audio_cgcr";

			label = "VA_TX";
			qcom,din-ports = <3>;
			qcom,dout-ports = <0>;

			qcom,ports-sinterval-low =	/bits/ 8 <0x03 0x03 0x03>;
			qcom,ports-offset1 =		/bits/ 8 <0x01 0x02 0x01>;
			qcom,ports-offset2 =		/bits/ 8 <0x00 0x00 0x00>;
			qcom,ports-hstart =		/bits/ 8 <0xff 0xff 0xff>;
			qcom,ports-hstop =		/bits/ 8 <0xff 0xff 0xff>;
			qcom,ports-word-length =	/bits/ 8 <0xff 0xff 0xff>;
			qcom,ports-block-pack-mode =	/bits/ 8 <0xff 0xff 0xff>;
			qcom,ports-block-group-count =	/bits/ 8 <0xff 0xff 0xff>;
			qcom,ports-lane-control =	/bits/ 8 <0x00 0x00 0x00>;

			#sound-dai-cells = <1>;
			#address-cells = <2>;
			#size-cells = <0>;

			status = "disabled";
		};

		lpasscc: clock-controller@a7e0000 {
			compatible = "qcom,sm6115-lpasscc";
			reg = <0x0 0x0a7e0000 0x0 0x12000>;
			#reset-cells = <1>;
		};

		remoteproc_cdsp: remoteproc@b300000 {
			compatible = "qcom,sm6115-cdsp-pas";
			reg = <0x0 0x0b300000 0x0 0x4040>;

			interrupts-extended = <&intc GIC_SPI 265 IRQ_TYPE_EDGE_RISING>,
					      <&cdsp_smp2p_in 0 IRQ_TYPE_EDGE_RISING>,
					      <&cdsp_smp2p_in 1 IRQ_TYPE_EDGE_RISING>,
					      <&cdsp_smp2p_in 2 IRQ_TYPE_EDGE_RISING>,
					      <&cdsp_smp2p_in 3 IRQ_TYPE_EDGE_RISING>;
			interrupt-names = "wdog", "fatal", "ready",
					  "handover", "stop-ack";

			clocks = <&rpmcc RPM_SMD_XO_CLK_SRC>;
			clock-names = "xo";

			power-domains = <&rpmpd SM6115_VDDCX>;

			memory-region = <&pil_cdsp_mem>;

			qcom,smem-states = <&cdsp_smp2p_out 0>;
			qcom,smem-state-names = "stop";

			status = "disabled";

			glink-edge {
				interrupts = <GIC_SPI 261 IRQ_TYPE_EDGE_RISING>;
				label = "cdsp";
				qcom,remote-pid = <5>;
				mboxes = <&apcs_glb 28>;

				fastrpc {
					compatible = "qcom,fastrpc";
					qcom,glink-channels = "fastrpcglink-apps-dsp";
					label = "cdsp";
					#address-cells = <1>;
					#size-cells = <0>;

					compute-cb@1 {
						compatible = "qcom,fastrpc-compute-cb";
						reg = <1>;
						iommus = <&apps_smmu 0x0c01 0x0>;
					};

					compute-cb@2 {
						compatible = "qcom,fastrpc-compute-cb";
						reg = <2>;
						iommus = <&apps_smmu 0x0c02 0x0>;
					};

					compute-cb@3 {
						compatible = "qcom,fastrpc-compute-cb";
						reg = <3>;
						iommus = <&apps_smmu 0x0c03 0x0>;
					};

					compute-cb@4 {
						compatible = "qcom,fastrpc-compute-cb";
						reg = <4>;
						iommus = <&apps_smmu 0x0c04 0x0>;
					};

					compute-cb@5 {
						compatible = "qcom,fastrpc-compute-cb";
						reg = <5>;
						iommus = <&apps_smmu 0x0c05 0x0>;
					};

					compute-cb@6 {
						compatible = "qcom,fastrpc-compute-cb";
						reg = <6>;
						iommus = <&apps_smmu 0x0c06 0x0>;
					};

					compute-cb@9 {
						compatible = "qcom,fastrpc-compute-cb";
						reg = <9>;
						iommus = <&apps_smmu 0x0c09 0x0>;
					};
				};
			};
		};

		apps_smmu: iommu@c600000 {
			compatible = "qcom,sm6115-smmu-500", "qcom,smmu-500", "arm,mmu-500";
			reg = <0x0 0x0c600000 0x0 0x80000>;
			#iommu-cells = <2>;
			#global-interrupts = <1>;

			interrupts = <GIC_SPI 81 IRQ_TYPE_LEVEL_HIGH>,
				     <GIC_SPI 88 IRQ_TYPE_LEVEL_HIGH>,
				     <GIC_SPI 89 IRQ_TYPE_LEVEL_HIGH>,
				     <GIC_SPI 90 IRQ_TYPE_LEVEL_HIGH>,
				     <GIC_SPI 91 IRQ_TYPE_LEVEL_HIGH>,
				     <GIC_SPI 92 IRQ_TYPE_LEVEL_HIGH>,
				     <GIC_SPI 93 IRQ_TYPE_LEVEL_HIGH>,
				     <GIC_SPI 94 IRQ_TYPE_LEVEL_HIGH>,
				     <GIC_SPI 95 IRQ_TYPE_LEVEL_HIGH>,
				     <GIC_SPI 96 IRQ_TYPE_LEVEL_HIGH>,
				     <GIC_SPI 97 IRQ_TYPE_LEVEL_HIGH>,
				     <GIC_SPI 98 IRQ_TYPE_LEVEL_HIGH>,
				     <GIC_SPI 99 IRQ_TYPE_LEVEL_HIGH>,
				     <GIC_SPI 100 IRQ_TYPE_LEVEL_HIGH>,
				     <GIC_SPI 101 IRQ_TYPE_LEVEL_HIGH>,
				     <GIC_SPI 102 IRQ_TYPE_LEVEL_HIGH>,
				     <GIC_SPI 103 IRQ_TYPE_LEVEL_HIGH>,
				     <GIC_SPI 104 IRQ_TYPE_LEVEL_HIGH>,
				     <GIC_SPI 105 IRQ_TYPE_LEVEL_HIGH>,
				     <GIC_SPI 106 IRQ_TYPE_LEVEL_HIGH>,
				     <GIC_SPI 107 IRQ_TYPE_LEVEL_HIGH>,
				     <GIC_SPI 108 IRQ_TYPE_LEVEL_HIGH>,
				     <GIC_SPI 109 IRQ_TYPE_LEVEL_HIGH>,
				     <GIC_SPI 110 IRQ_TYPE_LEVEL_HIGH>,
				     <GIC_SPI 111 IRQ_TYPE_LEVEL_HIGH>,
				     <GIC_SPI 112 IRQ_TYPE_LEVEL_HIGH>,
				     <GIC_SPI 113 IRQ_TYPE_LEVEL_HIGH>,
				     <GIC_SPI 114 IRQ_TYPE_LEVEL_HIGH>,
				     <GIC_SPI 115 IRQ_TYPE_LEVEL_HIGH>,
				     <GIC_SPI 116 IRQ_TYPE_LEVEL_HIGH>,
				     <GIC_SPI 117 IRQ_TYPE_LEVEL_HIGH>,
				     <GIC_SPI 118 IRQ_TYPE_LEVEL_HIGH>,
				     <GIC_SPI 119 IRQ_TYPE_LEVEL_HIGH>,
				     <GIC_SPI 120 IRQ_TYPE_LEVEL_HIGH>,
				     <GIC_SPI 121 IRQ_TYPE_LEVEL_HIGH>,
				     <GIC_SPI 122 IRQ_TYPE_LEVEL_HIGH>,
				     <GIC_SPI 123 IRQ_TYPE_LEVEL_HIGH>,
				     <GIC_SPI 124 IRQ_TYPE_LEVEL_HIGH>,
				     <GIC_SPI 125 IRQ_TYPE_LEVEL_HIGH>,
				     <GIC_SPI 126 IRQ_TYPE_LEVEL_HIGH>,
				     <GIC_SPI 127 IRQ_TYPE_LEVEL_HIGH>,
				     <GIC_SPI 128 IRQ_TYPE_LEVEL_HIGH>,
				     <GIC_SPI 129 IRQ_TYPE_LEVEL_HIGH>,
				     <GIC_SPI 130 IRQ_TYPE_LEVEL_HIGH>,
				     <GIC_SPI 131 IRQ_TYPE_LEVEL_HIGH>,
				     <GIC_SPI 132 IRQ_TYPE_LEVEL_HIGH>,
				     <GIC_SPI 133 IRQ_TYPE_LEVEL_HIGH>,
				     <GIC_SPI 134 IRQ_TYPE_LEVEL_HIGH>,
				     <GIC_SPI 135 IRQ_TYPE_LEVEL_HIGH>,
				     <GIC_SPI 136 IRQ_TYPE_LEVEL_HIGH>,
				     <GIC_SPI 137 IRQ_TYPE_LEVEL_HIGH>,
				     <GIC_SPI 138 IRQ_TYPE_LEVEL_HIGH>,
				     <GIC_SPI 139 IRQ_TYPE_LEVEL_HIGH>,
				     <GIC_SPI 140 IRQ_TYPE_LEVEL_HIGH>,
				     <GIC_SPI 141 IRQ_TYPE_LEVEL_HIGH>,
				     <GIC_SPI 142 IRQ_TYPE_LEVEL_HIGH>,
				     <GIC_SPI 143 IRQ_TYPE_LEVEL_HIGH>,
				     <GIC_SPI 144 IRQ_TYPE_LEVEL_HIGH>,
				     <GIC_SPI 145 IRQ_TYPE_LEVEL_HIGH>,
				     <GIC_SPI 146 IRQ_TYPE_LEVEL_HIGH>,
				     <GIC_SPI 147 IRQ_TYPE_LEVEL_HIGH>,
				     <GIC_SPI 148 IRQ_TYPE_LEVEL_HIGH>,
				     <GIC_SPI 149 IRQ_TYPE_LEVEL_HIGH>,
				     <GIC_SPI 150 IRQ_TYPE_LEVEL_HIGH>,
				     <GIC_SPI 151 IRQ_TYPE_LEVEL_HIGH>;
		};

		wifi: wifi@c800000 {
			compatible = "qcom,wcn3990-wifi";
			reg = <0x0 0x0c800000 0x0 0x800000>;
			reg-names = "membase";
			clock = <&rpmcc RPM_SMD_RF_CLK2>;
			clock-names = "cxo_ref_clk_pin";
			memory-region = <&wlan_msa_mem>;
			interrupts = <GIC_SPI 358 IRQ_TYPE_LEVEL_HIGH>,
				     <GIC_SPI 359 IRQ_TYPE_LEVEL_HIGH>,
				     <GIC_SPI 360 IRQ_TYPE_LEVEL_HIGH>,
				     <GIC_SPI 361 IRQ_TYPE_LEVEL_HIGH>,
				     <GIC_SPI 362 IRQ_TYPE_LEVEL_HIGH>,
				     <GIC_SPI 363 IRQ_TYPE_LEVEL_HIGH>,
				     <GIC_SPI 364 IRQ_TYPE_LEVEL_HIGH>,
				     <GIC_SPI 365 IRQ_TYPE_LEVEL_HIGH>,
				     <GIC_SPI 366 IRQ_TYPE_LEVEL_HIGH>,
				     <GIC_SPI 367 IRQ_TYPE_LEVEL_HIGH>,
				     <GIC_SPI 368 IRQ_TYPE_LEVEL_HIGH>,
				     <GIC_SPI 369 IRQ_TYPE_LEVEL_HIGH>;
			iommus = <&apps_smmu 0x1a0 0x1>;
			qcom,msa-fixed-perm;
			status = "disabled";
		};

		watchdog@f017000 {
			compatible = "qcom,apss-wdt-sm6115", "qcom,kpss-wdt";
			reg = <0x0 0x0f017000 0x0 0x1000>;
			clocks = <&sleep_clk>;
			interrupts = <GIC_SPI 3 IRQ_TYPE_EDGE_RISING>;
		};

		apcs_glb: mailbox@f111000 {
			compatible = "qcom,sm6115-apcs-hmss-global",
				     "qcom,msm8994-apcs-kpss-global";
			reg = <0x0 0x0f111000 0x0 0x1000>;

			#mbox-cells = <1>;
		};

		timer@f120000 {
			compatible = "arm,armv7-timer-mem";
			reg = <0x0 0x0f120000 0x0 0x1000>;
			#address-cells = <2>;
			#size-cells = <1>;
			ranges = <0x0 0x0 0x0 0x0 0x20000000>;
			clock-frequency = <19200000>;

			frame@f121000 {
				reg = <0x0 0x0f121000 0x1000>, <0x0 0x0f122000 0x1000>;
				frame-number = <0>;
				interrupts = <GIC_SPI 8 IRQ_TYPE_LEVEL_HIGH>,
					     <GIC_SPI 7 IRQ_TYPE_LEVEL_HIGH>;
			};

			frame@f123000 {
				reg = <0x0 0x0f123000 0x1000>;
				frame-number = <1>;
				interrupts = <GIC_SPI 9 IRQ_TYPE_LEVEL_HIGH>;
				status = "disabled";
			};

			frame@f124000 {
				reg = <0x0 0x0f124000 0x1000>;
				frame-number = <2>;
				interrupts = <GIC_SPI 10 IRQ_TYPE_LEVEL_HIGH>;
				status = "disabled";
			};

			frame@f125000 {
				reg = <0x0 0x0f125000 0x1000>;
				frame-number = <3>;
				interrupts = <GIC_SPI 11 IRQ_TYPE_LEVEL_HIGH>;
				status = "disabled";
			};

			frame@f126000 {
				reg = <0x0 0x0f126000 0x1000>;
				frame-number = <4>;
				interrupts = <GIC_SPI 12 IRQ_TYPE_LEVEL_HIGH>;
				status = "disabled";
			};

			frame@f127000 {
				reg = <0x0 0x0f127000 0x1000>;
				frame-number = <5>;
				interrupts = <GIC_SPI 13 IRQ_TYPE_LEVEL_HIGH>;
				status = "disabled";
			};

			frame@f128000 {
				reg = <0x0 0x0f128000 0x1000>;
				frame-number = <6>;
				interrupts = <GIC_SPI 14 IRQ_TYPE_LEVEL_HIGH>;
				status = "disabled";
			};
		};

		intc: interrupt-controller@f200000 {
			compatible = "arm,gic-v3";
			reg = <0x0 0x0f200000 0x0 0x10000>,
			      <0x0 0x0f300000 0x0 0x100000>;
			#interrupt-cells = <3>;
			interrupt-controller;
			interrupt-parent = <&intc>;
			#redistributor-regions = <1>;
			redistributor-stride = <0x0 0x20000>;
			interrupts = <GIC_PPI 9 IRQ_TYPE_LEVEL_HIGH>;
		};

		cpufreq_hw: cpufreq@f521000 {
			compatible = "qcom,sm6115-cpufreq-hw", "qcom,cpufreq-hw";
			reg = <0x0 0x0f521000 0x0 0x1000>,
			      <0x0 0x0f523000 0x0 0x1000>;

			reg-names = "freq-domain0", "freq-domain1";
			clocks = <&rpmcc RPM_SMD_XO_CLK_SRC>, <&gcc GPLL0>;
			clock-names = "xo", "alternate";

			#freq-domain-cells = <1>;
			#clock-cells = <1>;
		};

		cci: cci@5c1b000 {
			compatible = "qcom,sm6225-cci", "qcom,msm8996-cci";
			reg = <0x0 0x05c1b000 0x0 0x1000>;

			interrupts = <GIC_SPI 206 IRQ_TYPE_EDGE_RISING>;

			assigned-clocks = <&gcc GCC_CAMSS_CCI_CLK_SRC>;
			assigned-clock-rates = <37500000>;

			clocks = <&gcc GCC_CAMSS_TOP_AHB_CLK>,
				 <&gcc GCC_CAMSS_CCI_0_CLK>;
			clock-names = "ahb", "cci";

			power-domains = <&gcc GCC_CAMSS_TOP_GDSC>;
			pinctrl-names = "default", "sleep";
			pinctrl-0 = <&cci0_default &cci1_default>;
			pinctrl-1 = <&cci0_sleep &cci1_sleep>;

			#address-cells = <1>;
			#size-cells = <0>;
			status = "disabled";

			cci_i2c0: i2c-bus@0 {
				reg = <0>;
				clock-frequency = <100000>;
				#address-cells = <1>;
				#size-cells = <0>;
			};

			cci_i2c1: i2c-bus@1 {
				reg = <1>;
				clock-frequency = <100000>;
				#address-cells = <1>;
				#size-cells = <0>;
			};
		};

		camss: camss@5c11000 {
			compatible = "qcom,sm6225-camss";

			reg = <0x0 0x05c11000 0x0 0x1000>,
			      <0x0 0x05c6e000 0x0 0x1000>,
			      <0x0 0x05c75000 0x0 0x1000>,
			      <0x0 0x05c7c000 0x0 0x1000>,
			      <0x0 0x05c52000 0x0 0x2000>,
			      <0x0 0x05c54000 0x0 0x2000>,
			      <0x0 0x05c56000 0x0 0x2000>,
			      <0x0 0x05c66000 0x0 0x0400>,
			      <0x0 0x05c68000 0x0 0x0400>,
			      <0x0 0x05c6f000 0x0 0x4000>,
			      <0x0 0x05c76000 0x0 0x4000>,
			      <0x0 0x05c7d000 0x0 0x4000>;
			reg-names = "top",
				    "csid0", "csid1", "csid2",
				    "csiphy0", "csiphy1", "csiphy2",
				    "csitpg0", "csitpg1",
				    "vfe0", "vfe1", "vfe2";

			clocks = <&gcc GCC_CAMERA_AHB_CLK>,
				 <&gcc GCC_CAMSS_AXI_CLK>,
				 <&gcc GCC_CAMSS_NRT_AXI_CLK>,
				 <&gcc GCC_CAMSS_RT_AXI_CLK>,
				 <&gcc GCC_CAMSS_TFE_0_CSID_CLK>,
				 <&gcc GCC_CAMSS_TFE_1_CSID_CLK>,
				 <&gcc GCC_CAMSS_TFE_2_CSID_CLK>,
				 <&gcc GCC_CAMSS_CPHY_0_CLK>,
				 <&gcc GCC_CAMSS_CSI0PHYTIMER_CLK>,
				 <&gcc GCC_CAMSS_CPHY_1_CLK>,
				 <&gcc GCC_CAMSS_CSI1PHYTIMER_CLK>,
				 <&gcc GCC_CAMSS_CPHY_2_CLK>,
				 <&gcc GCC_CAMSS_CSI2PHYTIMER_CLK>,
				 <&gcc GCC_CAMSS_TOP_AHB_CLK>,
				 <&gcc GCC_CAMSS_TFE_0_CLK>,
				 <&gcc GCC_CAMSS_TFE_0_CPHY_RX_CLK>,
				 <&gcc GCC_CAMSS_TFE_1_CLK>,
				 <&gcc GCC_CAMSS_TFE_1_CPHY_RX_CLK>,
				 <&gcc GCC_CAMSS_TFE_2_CLK>,
				 <&gcc GCC_CAMSS_TFE_2_CPHY_RX_CLK>;
			clock-names = "ahb",
				      "axi",
				      "camnoc_nrt_axi",
				      "camnoc_rt_axi",
				      "csi0", "csi1", "csi2",
				      "csiphy0", "csiphy0_timer",
				      "csiphy1", "csiphy1_timer",
				      "csiphy2", "csiphy2_timer",
				      "top_ahb",
				      "vfe0", "vfe0_cphy_rx",
				      "vfe1", "vfe1_cphy_rx",
				      "vfe2", "vfe2_cphy_rx";

			interrupts = <GIC_SPI 210 IRQ_TYPE_EDGE_RISING>,
				     <GIC_SPI 212 IRQ_TYPE_EDGE_RISING>,
				     <GIC_SPI 77  IRQ_TYPE_EDGE_RISING>,
				     <GIC_SPI 72  IRQ_TYPE_EDGE_RISING>,
				     <GIC_SPI 73  IRQ_TYPE_EDGE_RISING>,
				     <GIC_SPI 74  IRQ_TYPE_EDGE_RISING>,
				     <GIC_SPI 214 IRQ_TYPE_EDGE_RISING>,
				     <GIC_SPI 215 IRQ_TYPE_EDGE_RISING>,
				     <GIC_SPI 211 IRQ_TYPE_EDGE_RISING>,
				     <GIC_SPI 213 IRQ_TYPE_EDGE_RISING>,
				     <GIC_SPI 78  IRQ_TYPE_EDGE_RISING>;
			interrupt-names = "csid0", "csid1", "csid2",
					  "csiphy0", "csiphy1", "csiphy2",
					  "csitpg0", "csitpg1",
					  "vfe0", "vfe1", "vfe2";

			interconnects = <&bimc MASTER_AMPSS_M0 RPM_ACTIVE_TAG
					&config_noc SLAVE_CAMERA_CFG RPM_ACTIVE_TAG>,
					<&mmrt_virt MASTER_CAMNOC_HF RPM_ALWAYS_TAG
					&bimc SLAVE_EBI_CH0 RPM_ALWAYS_TAG>,
					<&mmnrt_virt MASTER_CAMNOC_SF RPM_ALWAYS_TAG
					&bimc SLAVE_EBI_CH0 RPM_ALWAYS_TAG>;
			interconnect-names = "ahb", "hf_mnoc", "sf_mnoc";

			iommus = <&apps_smmu 0x400 0x0>,
				 <&apps_smmu 0x800 0x0>,
				 <&apps_smmu 0x820 0x0>,
				 <&apps_smmu 0x840 0x0>;

			/* NOTE: TITAN_TOP GDSC must stay last: the driver
			 * attaches it by legacy index (genpd_num - 1). */
			power-domains = <&rpmpd SM6115_VDDMX>, <&rpmpd SM6115_VDDCX>, <&gcc GCC_CAMSS_TOP_GDSC>;
			power-domain-names = "mx", "cx", "top";
			operating-points-v2 = <&camss_opp_table>;

			vdd-csiphy-1p2-supply = <&pm6125_l4>;
			vdd-csiphy-1p8-supply = <&pm6125_l18>;

			status = "disabled";

			camss_opp_table: opp-table {
				compatible = "operating-points-v2";

				/* Rails need is rate-independent (GPLL10 is fixed
				 * at 1152 MHz and needs MX above its LOW corner;
				 * TFE logic needs CX at LOW_L1 for top rates):
				 * single flat entry. LOW_L1 ~= SVS_PLUS per
				 * the venus OPP mapping precedent; refine
				 * per-rate if DVFS is ever needed. */
				opp-460800000 {
					opp-hz = /bits/ 64 <460800000>;
					required-opps = <&rpmpd_opp_svs_plus>, <&rpmpd_opp_svs_plus>;
				};
			};

			ports {
				#address-cells = <1>;
				#size-cells = <0>;

				port@0 {
					reg = <0>;
				};

				port@1 {
					reg = <1>;
				};

				port@2 {
					reg = <2>;
				};
			};
		};

		venus: video-codec@5a00000 {
			compatible = "qcom,sm6225-venus", "qcom,qcm2290-venus";
			reg = <0x0 0x5a00000 0x0 0x200000>;
			interrupts = <GIC_SPI 225 IRQ_TYPE_LEVEL_HIGH>;

			power-domains = <&gcc GCC_VENUS_GDSC>,
					<&gcc GCC_VCODEC0_GDSC>,
					<&rpmpd SM6115_VDDCX>;
			power-domain-names = "venus", "vcodec0", "cx";

			operating-points-v2 = <&venus_opp_table>;

			clocks = <&gcc GCC_VIDEO_VENUS_CTL_CLK>,
				 <&gcc GCC_VIDEO_AHB_CLK>,
				 <&gcc GCC_VENUS_CTL_AXI_CLK>,
				 <&gcc GCC_VIDEO_THROTTLE_CORE_CLK>,
				 <&gcc GCC_VIDEO_VCODEC0_SYS_CLK>,
				 <&gcc GCC_VCODEC0_AXI_CLK>;
			clock-names = "core", "iface", "bus", "throttle",
				      "vcodec0_core", "vcodec0_bus";

			memory-region = <&pil_video_mem>;
			iommus = <&apps_smmu 0x860 0x0>, <&apps_smmu 0x880 0x0>;

			interconnects = <&mmnrt_virt MASTER_VIDEO_P0 RPM_ALWAYS_TAG
					&bimc SLAVE_EBI_CH0 RPM_ALWAYS_TAG>,
					<&bimc MASTER_AMPSS_M0 RPM_ACTIVE_TAG
					&config_noc SLAVE_VENUS_CFG RPM_ACTIVE_TAG>;
			interconnect-names = "video-mem", "cpu-cfg";

			status = "disabled";

			venus_opp_table: opp-table {
				compatible = "operating-points-v2";

				opp-133330000 {
					opp-hz = /bits/ 64 <133330000>;
					required-opps = <&rpmpd_opp_low_svs>;
				};
				opp-240000000 {
					opp-hz = /bits/ 64 <240000000>;
					required-opps = <&rpmpd_opp_svs>;
				};
				opp-300000000 {
					opp-hz = /bits/ 64 <300000000>;
					required-opps = <&rpmpd_opp_svs_plus>;
				};
				opp-384000000 {
					opp-hz = /bits/ 64 <384000000>;
					required-opps = <&rpmpd_opp_nom>;
				};
			};
		};
	};

	thermal-zones {
		mapss-thermal {
			thermal-sensors = <&tsens0 0>;

			trips {
				trip-point0 {
					temperature = <115000>;
					hysteresis = <5000>;
					type = "passive";
				};

				trip-point1 {
					temperature = <125000>;
					hysteresis = <1000>;
					type = "passive";
				};
			};
		};

		cdsp-hvx-thermal {
			thermal-sensors = <&tsens0 1>;

			trips {
				trip-point0 {
					temperature = <115000>;
					hysteresis = <5000>;
					type = "passive";
				};

				trip-point1 {
					temperature = <125000>;
					hysteresis = <1000>;
					type = "passive";
				};
			};
		};

		wlan-thermal {
			thermal-sensors = <&tsens0 2>;

			trips {
				trip-point0 {
					temperature = <115000>;
					hysteresis = <5000>;
					type = "passive";
				};

				trip-point1 {
					temperature = <125000>;
					hysteresis = <1000>;
					type = "passive";
				};
			};
		};

		camera-thermal {
			thermal-sensors = <&tsens0 3>;

			trips {
				trip-point0 {
					temperature = <115000>;
					hysteresis = <5000>;
					type = "passive";
				};

				trip-point1 {
					temperature = <125000>;
					hysteresis = <1000>;
					type = "passive";
				};
			};
		};

		video-thermal {
			thermal-sensors = <&tsens0 4>;

			trips {
				trip-point0 {
					temperature = <115000>;
					hysteresis = <5000>;
					type = "passive";
				};

				trip-point1 {
					temperature = <125000>;
					hysteresis = <1000>;
					type = "passive";
				};
			};
		};

		modem1-thermal {
			thermal-sensors = <&tsens0 5>;

			trips {
				trip-point0 {
					temperature = <115000>;
					hysteresis = <5000>;
					type = "passive";
				};

				trip-point1 {
					temperature = <125000>;
					hysteresis = <1000>;
					type = "passive";
				};
			};
		};

		cpu4-thermal {
			thermal-sensors = <&tsens0 6>;

			trips {
				cpu4_alert0: trip-point0 {
					temperature = <90000>;
					hysteresis = <2000>;
					type = "passive";
				};

				cpu4_alert1: trip-point1 {
					temperature = <95000>;
					hysteresis = <2000>;
					type = "passive";
				};

				cpu4_crit: cpu-crit {
					temperature = <110000>;
					hysteresis = <1000>;
					type = "critical";
				};
			};
		};

		cpu5-thermal {
			thermal-sensors = <&tsens0 7>;

			trips {
				cpu5_alert0: trip-point0 {
					temperature = <90000>;
					hysteresis = <2000>;
					type = "passive";
				};

				cpu5_alert1: trip-point1 {
					temperature = <95000>;
					hysteresis = <2000>;
					type = "passive";
				};

				cpu5_crit: cpu-crit {
					temperature = <110000>;
					hysteresis = <1000>;
					type = "critical";
				};
			};
		};

		cpu6-thermal {
			thermal-sensors = <&tsens0 8>;

			trips {
				cpu6_alert0: trip-point0 {
					temperature = <90000>;
					hysteresis = <2000>;
					type = "passive";
				};

				cpu6_alert1: trip-point1 {
					temperature = <95000>;
					hysteresis = <2000>;
					type = "passive";
				};

				cpu6_crit: cpu-crit {
					temperature = <110000>;
					hysteresis = <1000>;
					type = "critical";
				};
			};
		};

		cpu7-thermal {
			thermal-sensors = <&tsens0 9>;

			trips {
				cpu7_alert0: trip-point0 {
					temperature = <90000>;
					hysteresis = <2000>;
					type = "passive";
				};

				cpu7_alert1: trip-point1 {
					temperature = <95000>;
					hysteresis = <2000>;
					type = "passive";
				};

				cpu7_crit: cpu-crit {
					temperature = <110000>;
					hysteresis = <1000>;
					type = "critical";
				};
			};
		};

		cpu45-thermal {
			thermal-sensors = <&tsens0 10>;

			trips {
				cpu45_alert0: trip-point0 {
					temperature = <90000>;
					hysteresis = <2000>;
					type = "passive";
				};

				cpu45_alert1: trip-point1 {
					temperature = <95000>;
					hysteresis = <2000>;
					type = "passive";
				};

				cpu45_crit: cpu-crit {
					temperature = <110000>;
					hysteresis = <1000>;
					type = "critical";
				};
			};
		};

		cpu67-thermal {
			thermal-sensors = <&tsens0 11>;

			trips {
				cpu67_alert0: trip-point0 {
					temperature = <90000>;
					hysteresis = <2000>;
					type = "passive";
				};

				cpu67_alert1: trip-point1 {
					temperature = <95000>;
					hysteresis = <2000>;
					type = "passive";
				};

				cpu67_crit: cpu-crit {
					temperature = <110000>;
					hysteresis = <1000>;
					type = "critical";
				};
			};
		};

		cpu0123-thermal {
			thermal-sensors = <&tsens0 12>;

			trips {
				cpu0123_alert0: trip-point0 {
					temperature = <90000>;
					hysteresis = <2000>;
					type = "passive";
				};

				cpu0123_alert1: trip-point1 {
					temperature = <95000>;
					hysteresis = <2000>;
					type = "passive";
				};

				cpu0123_crit: cpu-crit {
					temperature = <110000>;
					hysteresis = <1000>;
					type = "critical";
				};
			};
		};

		modem0-thermal {
			thermal-sensors = <&tsens0 13>;

			trips {
				trip-point0 {
					temperature = <115000>;
					hysteresis = <5000>;
					type = "passive";
				};

				trip-point1 {
					temperature = <125000>;
					hysteresis = <1000>;
					type = "passive";
				};
			};
		};

		display-thermal {
			thermal-sensors = <&tsens0 14>;

			trips {
				trip-point0 {
					temperature = <115000>;
					hysteresis = <5000>;
					type = "passive";
				};

				trip-point1 {
					temperature = <125000>;
					hysteresis = <1000>;
					type = "passive";
				};
			};
		};

		gpu-thermal {
			polling-delay-passive = <250>;

			thermal-sensors = <&tsens0 15>;

			cooling-maps {
				map0 {
					trip = <&gpu_alert0>;
					cooling-device = <&gpu THERMAL_NO_LIMIT THERMAL_NO_LIMIT>;
				};
			};

			trips {
				gpu_alert0: trip-point0 {
					temperature = <85000>;
					hysteresis = <1000>;
					type = "passive";
				};

				trip-point1 {
					temperature = <110000>;
					hysteresis = <1000>;
					type = "critical";
				};
			};
		};
	};

	timer {
		compatible = "arm,armv8-timer", "arm,armv7-timer";
		interrupts = <GIC_PPI 1 (GIC_CPU_MASK_SIMPLE(4) | IRQ_TYPE_LEVEL_LOW)>,
			     <GIC_PPI 2 (GIC_CPU_MASK_SIMPLE(4) | IRQ_TYPE_LEVEL_LOW)>,
			     <GIC_PPI 3 (GIC_CPU_MASK_SIMPLE(4) | IRQ_TYPE_LEVEL_LOW)>,
			     <GIC_PPI 0 (GIC_CPU_MASK_SIMPLE(4) | IRQ_TYPE_LEVEL_LOW)>;
		clock-frequency = <19200000>;
	};
};
